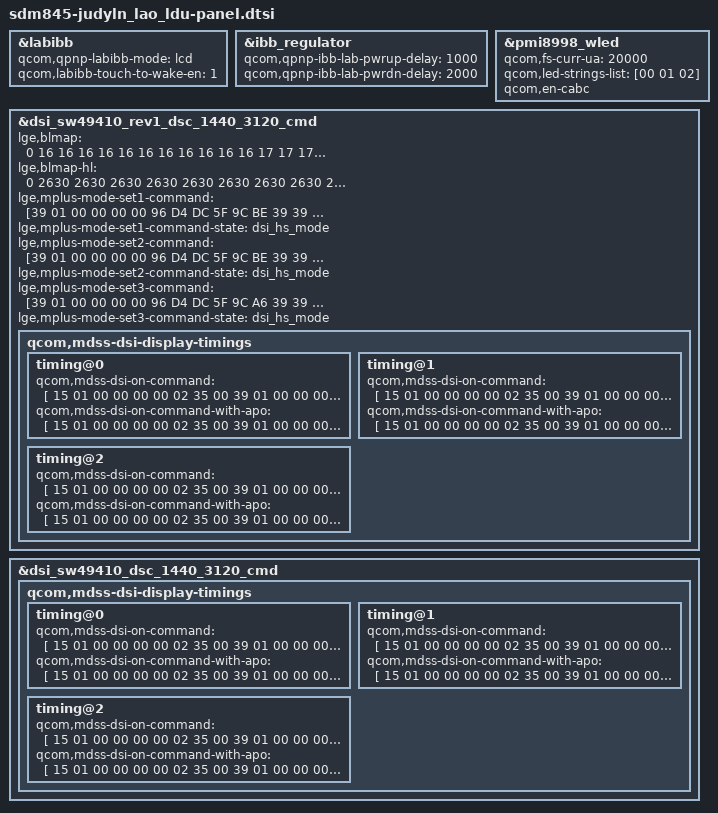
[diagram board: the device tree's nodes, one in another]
/* Copyright (c) 2017, The Linux Foundation. All rights reserved.
 *
 * This program is free software; you can redistribute it and/or modify
 * it under the terms of the GNU General Public License version 2 and
 * only version 2 as published by the Free Software Foundation.
 *
 * This program is distributed in the hope that it will be useful,
 * but WITHOUT ANY WARRANTY; without even the implied warranty of
 * MERCHANTABILITY or FITNESS FOR A PARTICULAR PURPOSE.  See the
 * GNU General Public License for more details.
 */

#include "../sdm845-judy_common/sdm845-judy_common-panel.dtsi"

&labibb {
	status = "ok";
	qcom,qpnp-labibb-mode = "lcd";
	qcom,labibb-touch-to-wake-en = <1>;
};

&ibb_regulator {
	qcom,qpnp-ibb-lab-pwrup-delay = <1000>;
	qcom,qpnp-ibb-lab-pwrdn-delay = <2000>;
};

&pmi8998_wled {
	status = "okay";
	qcom,fs-curr-ua = <20000>;
	qcom,led-strings-list = [00 01 02];
	qcom,en-cabc;
	/delete-property/ qcom,auto-calibration-enable;
};

&dsi_sw49410_rev1_dsc_1440_3120_cmd {
	lge,blmap = <
		0
		16 16 16 16 16 16 16 16 16 16 16 17 17 17 18 18 18 18 19 19
		19 20 20 21 22 23 24 25 26 27 28 29 30 31 32 34 36 38 40 42
		44 45 47 49 51 53 55 57 60 63 66 69 72 75 78 81 84 87 90 93
		97 101 105 109 113 118 122 126 130 134 138 142 147 152 157 162 167 173 178 183
		188 193 198 203 209 215 221 227 233 239 244 250 256 262 268 274 280 287 295 302
		309 317 324 331 339 346 353 361 368 377 386 394 403 412 421 429 438 447 456 464
		473 482 492 501 511 520 530 539 548 558 567 577 586 596 606 616 626 636 646 655
		665 675 685 695 705 715 727 739 751 763 775 788 800 812 824 836 848 860 873 887
		900 913 926 940 953 966 979 993 1006 1019 1034 1048 1063 1077 1092 1107 1121 1136 1150 1165
		1179 1194 1209 1223 1238 1253 1267 1282 1297 1312 1326 1341 1356 1370 1385 1403 1420 1438 1456 1473
		1491 1509 1526 1544 1562 1579 1597 1616 1635 1654 1673 1692 1711 1730 1749 1768 1787 1806 1825 1846
		1866 1887 1908 1928 1949 1970 1990 2011 2032 2052 2073 2093 2114 2134 2155 2175 2195 2216 2236 2256
		2277 2297 2318 2338 2365 2391 2418 2444 2471 2497 2524 2550 2577 2603 2630
	>;

	lge,blmap-hl = <
		0
		2630 2630 2630 2630 2630 2630 2630 2630 2630 2630
	>;

	lge,mplus-mode-set1-command = [39 01 00 00 00 00 96 D4 DC 5F 9C BE 39 39 39 47 48 48 48 3A 00 03 6D 80 00 00 8C 66 00 00 8C 66 00 00 8C 66 00 0A 48 80 00 0A 48 80 00 0A 48 80 00 0A 48 80 20 0A 14 0A 18 00 23 9E 23 9E 23 9E 01 01 01 01 04 04 04 04 01 00 02 80 00 10 00 10 00 10 13 9E 13 9E 13 9E 13 9E 05 05 05 05 05 05 05 05 23 9E FF FF 16 66 18 00 16 66 10 00 FF 01 00 02 00 03 00 04 00 05 00 06 00 07 00 08 00 09 00 0A 00 0B 00 0C 00 0D 00 0E 00 0F 00 1B 25 DC 18 00 20 00 1C E1 00 FF E0 C8 C8 41 8F];
	lge,mplus-mode-set1-command-state = "dsi_hs_mode";

	lge,mplus-mode-set2-command = [39 01 00 00 00 00 96 D4 DC 5F 9C BE 39 39 39 47 48 48 48 3A 00 03 6D 80 00 00 8C 66 00 00 8C 66 00 00 8C 66 00 0A 48 80 00 0A 48 80 00 0A 48 80 00 0A 48 80 20 0A 14 0A 18 00 23 9E 23 9E 23 9E 01 01 01 01 04 04 04 04 01 00 02 80 00 10 00 10 00 10 13 9E 13 9E 13 9E 13 9E 05 05 05 05 05 05 05 05 23 9E FF FF 16 66 18 00 16 66 10 00 FF 01 00 02 00 03 00 04 00 05 00 06 00 07 00 08 00 09 00 0A 00 0B 00 0C 00 0D 00 0E 00 0F 00 1B 25 DC 18 00 20 00 1C E1 00 FF E0 C8 C8 41 8F];
	lge,mplus-mode-set2-command-state = "dsi_hs_mode";

	lge,mplus-mode-set3-command = [39 01 00 00 00 00 96 D4 DC 5F 9C A6 39 39 39 47 48 48 48 3A 00 22 47 00 00 2F FD 00 00 22 47 00 00 0D B6 00 00 89 1C 00 00 2F FD 00 00 22 47 00 00 0D B6 00 20 00 00 00 18 00 23 9E 23 9E 23 9E 06 06 06 06 05 05 05 05 01 00 02 80 00 C8 01 80 00 30 13 9E 13 9E 13 9E 13 9E 10 10 10 10 10 10 10 10 23 9E FF FF 18 00 18 00 16 66 10 00 FF 01 00 02 00 03 00 04 00 05 00 06 00 07 00 08 00 09 00 0A 00 0B 00 0C 00 0D 00 0E 00 0F 00 1B 25 DC 18 00 20 00 1C E1 00 FF E0 C8 C8 41 8F];
	lge,mplus-mode-set3-command-state = "dsi_hs_mode";
	qcom,mdss-dsi-display-timings {
		timing@0{
			qcom,mdss-dsi-on-command = [
				/* TE On */
				15 01 00 00 00 00 02 35 00
				/* Page Address Set */
				39 01 00 00 00 00 05 2B 00 00 0C 2F
				/* BLU Control */
				15 01 00 00 00 00 02 51 FF
				15 01 00 00 00 00 02 53 2C
				15 01 00 00 00 00 02 5E 00
				15 01 00 00 00 00 02 55 81
				/*Manufacturer protection*/
				15 01 00 00 00 00 02 B0 AC
				/*Source Control*/
				39 01 00 00 00 00 09 B3 04 04 28 08 5A 12 23 02
				/*Gate & Mux Control*/
				39 01 00 00 00 00 20 B4 11 04 02 02 02 02 02 01 01 01 01 01 01 D0 E4 E4 E4 93 4E 39 0A 10 18 25 24 00 00 00 00 00 00
				/*Sync Setup*/
				39 01 00 00 00 00 09 B5 2E 0F 10 C0 00 10 C0 00
				/*Panel Setting*/
				39 01 00 00 00 00 06 B6 03 05 0B B3 30
				/*Touch Timing Control*/
				39 01 00 00 00 00 20 B8 57 02 90 40 5D D0 05 00 00 18 22 04 01 02 90 40 4C C0 04 00 00 18 22 04 01 08 00 3A 86 83 00
				/*Touch Source Setting*/
				39 01 00 00 00 00 06 B9 64 64 2A 3F EE
				/*DSC Configuration*/
				39 01 00 00 00 00 0C BA 3D 1F 01 FF 01 3C 1F 01 FF 01 00
				/*Low Rate Refresh Setting*/
				39 01 00 00 00 00 05 BC 00 00 00 10
				/*Black Frame Setting*/
				39 01 00 00 00 00 03 BD 00 00
				/* U2 Corner Down */
				39 01 00 00 00 00 03 BF 4F 02
				/*Internal Oscillator Setting*/
				39 01 00 00 00 00 0B C0 00 04 18 07 11 11 3C 00 0A 0A
				/*Power Control1*/
				39 01 00 00 00 00 07 C1 01 00 F0 C2 CF 0C
				/*Power Control2*/
				39 01 00 00 00 00 09 C2 CC 44 44 20 22 26 21 00
				/*Power Control3*/
				39 01 00 00 00 00 13 C3 92 11 09 09 11 CC 02 02 A4 A4 02 A2 38 28 14 40 38 C0
				/*Vcom Setting*/
				39 01 00 00 00 00 03 C4 26 00
				/*Power Sequence Option Configuration*/
				39 01 00 00 00 00 06 C9 05 5D 03 04 00
				/*Abrupt Power Off Control*/
				39 01 00 00 00 00 03 CA 9B 10
				/*LFD Control*/
				39 01 00 00 00 00 06 CB F3 90 3D 30 CC
				/*Tail TFT Setting*/
				39 01 00 00 00 00 06 CC 00 40 50 90 41
				/*U2 Option*/
				39 01 00 00 00 00 03 CE 00 00
				/*Gamma*/
				39 01 00 00 00 00 A9 D0 12 05 20 1B 2C 28 3F 3D 4F 4F 66 66 6E 6E 76 76 80 80 88 88 95 95 3F 3F A2 A2 94 94 8B 8B 81 81 75 75 66 66 47 47 2D 2D 00 01 12 05 20 1B 2C 28 3F 3D 4f 4f 66 66 6e 6e 76 76 80 80 88 88 95 95 3F 3F A2 A2 94 94 8b 8b 81 81 75 75 66 66 47 47 2d 2d 00 01 12 05 20 1B 2C 28 3F 3D 4f 4f 66 66 6e 6e 76 76 80 80 88 88 95 95 3F 3F A2 A2 94 94 8b 8b 81 81 75 75 66 66 47 47 2d 2d 00 01 12 05 20 1B 2C 28 3F 3D 4f 4f 66 66 6e 6e 76 76 80 80 88 88 94 94 3F 3F A4 A4 95 95 8b 8b 81 81 75 75 66 66 47 47 2d 2d 00 01
				39 01 00 00 00 00 A9 D1 12 05 20 1B 2C 28 3F 3D 4F 4F 66 66 6E 6E 76 76 80 80 88 88 95 95 3F 3F A2 A2 94 94 8B 8B 81 81 75 75 66 66 47 47 2D 2D 00 01 12 05 20 1B 2C 28 3F 3D 4f 4f 66 66 6e 6e 76 76 80 80 88 88 95 95 3F 3F A2 A2 94 94 8b 8b 81 81 75 75 66 66 47 47 2d 2d 00 01 12 05 20 1B 2C 28 3F 3D 4f 4f 66 66 6e 6e 76 76 80 80 88 88 95 95 3F 3F A2 A2 94 94 8b 8b 81 81 75 75 66 66 47 47 2d 2d 00 01 12 05 20 1B 2C 28 3F 3D 4f 4f 66 66 6e 6e 76 76 80 80 88 88 94 94 3F 3F A4 A4 95 95 8b 8b 81 81 75 75 66 66 47 47 2d 2d 00 01
				39 01 00 00 00 00 A9 D2 12 05 20 1B 2C 28 3F 3D 4F 4F 66 66 6E 6E 76 76 80 80 88 88 95 95 3F 3F A2 A2 94 94 8B 8B 81 81 75 75 66 66 47 47 2D 2D 00 01 12 05 20 1B 2C 28 3F 3D 4f 4f 66 66 6e 6e 76 76 80 80 88 88 95 95 3F 3F A2 A2 94 94 8b 8b 81 81 75 75 66 66 47 47 2d 2d 00 01 12 05 20 1B 2C 28 3F 3D 4f 4f 66 66 6e 6e 76 76 80 80 88 88 95 95 3F 3F A2 A2 94 94 8b 8b 81 81 75 75 66 66 47 47 2d 2d 00 01 12 05 20 1B 2C 28 3F 3D 4f 4f 66 66 6e 6e 76 76 80 80 88 88 94 94 3F 3F A4 A4 95 95 8b 8b 81 81 75 75 66 66 47 47 2d 2d 00 01
				/* MPLUS Control */
				39 01 00 00 00 00 05 D3 12 01 00 00
				/*Mplus Setting*/
				39 01 00 00 00 00 96 D4 DC 5F 9C BE 39 39 39 47 48 48 48 3A 00 03 6D 80 00 00 8C 66 00 00 8C 66 00 00 8C 66 00 0A 48 80 00 0A 48 80 00 0A 48 80 00 0A 48 80 20 0A 14 0A 18 00 23 9E 23 9E 23 9E 01 01 01 01 04 04 04 04 01 00 02 80 00 10 00 10 00 10 13 9E 13 9E 13 9E 13 9E 05 05 05 05 05 05 05 05 23 9E FF FF 16 66 18 00 16 66 10 00 FF 01 00 02 00 03 00 04 00 05 00 06 00 07 00 08 00 09 00 0A 00 0B 00 0C 00 0D 00 0E 00 0F 00 1B 25 DC 18 00 20 00 1C E1 00 FF E0 C8 C8 41 8F
				/*Notch Up Gradation*/
				39 01 00 00 00 00 21 AD 01 02 03 04 05 06 06 06 06 06 06 06 06 06 06 06 20 40 60 90 C0 F0 FF FF FF FF FF FF FF FF FF FF
				/*Notch Down Gradation*/
				39 01 00 00 00 00 21 AE 01 02 03 04 05 06 06 06 06 06 06 06 06 06 06 06 20 40 60 90 C0 F0 FF FF FF FF FF FF FF FF FF FF
				/*GIP Setting*/
				39 01 00 00 00 00 1B E5 0B 0A 0C 00 02 04 06 08 0F 1B 02 1A 1A 0B 0A 0C 01 03 05 07 09 10 1B 03 1A 1A
				/*Mux Setting*/
				39 01 00 00 00 00 11 E6 11 12 13 14 15 16 17 18 11 12 13 14 15 16 17 18
				/*Test1*/
				39 01 00 00 00 00 07 ED 21 49 00 00 00 00
				/*BLU Control*/
				15 01 00 00 00 00 02 55 81
				/*Sharpness*/
				39 01 00 00 00 00 06 F3 00 01 00 0D 00
				39 01 00 00 00 00 0E F4 00 00 40 83 C5 00 01 00 00 00 00 00 00
				39 01 00 00 00 00 18 FB 20 40 60 80 a0 c0 e0 13 18 18 18 16 0D 0D 00 C7 CF D8 E1 EA F3 F9 FF
				/*Gamma Correction*/
				39 01 00 00 00 00 02 F5 00
				39 01 00 00 00 00 11 F6 40 40 40 40 40 40 40 40 00 00 00 00 00 00 00 00
				39 01 00 00 00 00 11 F7 40 40 40 40 40 40 40 40 00 00 00 00 00 00 00 00
				39 01 00 00 00 00 11 F8 40 40 40 40 40 40 40 40 00 00 00 00 00 00 00 00
				/*BLU PWM Control*/
				39 01 00 00 00 00 0E FC 13 70 D0 26 30 7C 02 FF 12 22 22 10 00
				/* Normal Display mode on */
				05 01 00 00 00 00 01 13
				/* Sleep Out + min 120ms */
				05 01 00 00 80 00 01 11
				/*Black Frame Setting*/
				39 01 00 00 00 00 03 BD 01 05
				05 01 00 00 05 00 01 29
			];

			qcom,mdss-dsi-on-command-with-apo = [
				/* TE On */
				15 01 00 00 00 00 02 35 00
				/* Page Address Set */
				39 01 00 00 00 00 05 2B 00 00 0C 2F
				/* BLU Control */
				15 01 00 00 00 00 02 51 FF
				15 01 00 00 00 00 02 53 2C
				15 01 00 00 00 00 02 5E 00
				15 01 00 00 00 00 02 55 81
				/*Manufacturer protection*/
				15 01 00 00 00 00 02 B0 AC
				/*Source Control*/
				39 01 00 00 00 00 09 B3 04 04 28 08 5A 12 23 02
				/*Gate & Mux Control*/
				39 01 00 00 00 00 20 B4 11 04 02 02 02 02 02 01 01 01 01 01 01 D0 E4 E4 E4 93 4E 39 0A 10 18 25 24 00 00 00 00 00 00
				/*Sync Setup*/
				39 01 00 00 00 00 09 B5 2E 0F 10 C0 00 10 C0 00
				/*Panel Setting*/
				39 01 00 00 00 00 06 B6 03 05 0B B3 30
				/*Touch Timing Control*/
				39 01 00 00 00 00 20 B8 57 02 90 40 5D D0 05 00 00 18 22 04 01 02 90 40 4C C0 04 00 00 18 22 04 01 08 00 3A 86 83 00
				/*Touch Source Setting*/
				39 01 00 00 00 00 06 B9 64 64 2A 3F EE
				/*DSC Configuration*/
				39 01 00 00 00 00 0C BA 3D 1F 01 FF 01 3C 1F 01 FF 01 00
				/*Low Rate Refresh Setting*/
				39 01 00 00 00 00 05 BC 00 00 00 10
				/*Black Frame Setting*/
				39 01 00 00 00 00 03 BD 00 00
				/* U2 Corner Down */
				39 01 00 00 00 00 03 BF 4F 02
				/*Internal Oscillator Setting*/
				39 01 00 00 00 00 0B C0 00 04 18 07 11 11 3C 00 0A 0A
				/*Power Control1*/
				39 01 00 00 00 00 07 C1 01 00 F0 C2 CF 0C
				/*Power Control2*/
				39 01 00 00 00 00 09 C2 CC 44 44 20 22 26 21 00
				/*Power Control3*/
				39 01 00 00 00 00 13 C3 92 11 09 09 11 CC 02 02 A4 A4 02 A2 38 28 14 40 38 C0
				/*Vcom Setting*/
				39 01 00 00 00 00 03 C4 26 00
				/*Power Sequence Option Configuration - source & vcom GND*/
				39 01 00 00 00 00 06 C9 01 54 03 04 00
				/*Abrupt Power Off Control*/
				39 01 00 00 00 00 03 CA 9B 10
				/*LFD Control*/
				39 01 00 00 00 00 06 CB F3 90 3D 30 CC
				/*Tail TFT Setting*/
				39 01 00 00 00 00 06 CC 00 40 50 90 41
				/*U2 Option*/
				39 01 00 00 00 00 03 CE 00 00
				/*Gamma*/
				39 01 00 00 00 00 A9 D0 12 05 20 1B 2C 28 3F 3D 4F 4F 66 66 6E 6E 76 76 80 80 88 88 95 95 3F 3F A2 A2 94 94 8B 8B 81 81 75 75 66 66 47 47 2D 2D 00 01 12 05 20 1B 2C 28 3F 3D 4f 4f 66 66 6e 6e 76 76 80 80 88 88 95 95 3F 3F A2 A2 94 94 8b 8b 81 81 75 75 66 66 47 47 2d 2d 00 01 12 05 20 1B 2C 28 3F 3D 4f 4f 66 66 6e 6e 76 76 80 80 88 88 95 95 3F 3F A2 A2 94 94 8b 8b 81 81 75 75 66 66 47 47 2d 2d 00 01 12 05 20 1B 2C 28 3F 3D 4f 4f 66 66 6e 6e 76 76 80 80 88 88 94 94 3F 3F A4 A4 95 95 8b 8b 81 81 75 75 66 66 47 47 2d 2d 00 01
				39 01 00 00 00 00 A9 D1 12 05 20 1B 2C 28 3F 3D 4F 4F 66 66 6E 6E 76 76 80 80 88 88 95 95 3F 3F A2 A2 94 94 8B 8B 81 81 75 75 66 66 47 47 2D 2D 00 01 12 05 20 1B 2C 28 3F 3D 4f 4f 66 66 6e 6e 76 76 80 80 88 88 95 95 3F 3F A2 A2 94 94 8b 8b 81 81 75 75 66 66 47 47 2d 2d 00 01 12 05 20 1B 2C 28 3F 3D 4f 4f 66 66 6e 6e 76 76 80 80 88 88 95 95 3F 3F A2 A2 94 94 8b 8b 81 81 75 75 66 66 47 47 2d 2d 00 01 12 05 20 1B 2C 28 3F 3D 4f 4f 66 66 6e 6e 76 76 80 80 88 88 94 94 3F 3F A4 A4 95 95 8b 8b 81 81 75 75 66 66 47 47 2d 2d 00 01
				39 01 00 00 00 00 A9 D2 12 05 20 1B 2C 28 3F 3D 4F 4F 66 66 6E 6E 76 76 80 80 88 88 95 95 3F 3F A2 A2 94 94 8B 8B 81 81 75 75 66 66 47 47 2D 2D 00 01 12 05 20 1B 2C 28 3F 3D 4f 4f 66 66 6e 6e 76 76 80 80 88 88 95 95 3F 3F A2 A2 94 94 8b 8b 81 81 75 75 66 66 47 47 2d 2d 00 01 12 05 20 1B 2C 28 3F 3D 4f 4f 66 66 6e 6e 76 76 80 80 88 88 95 95 3F 3F A2 A2 94 94 8b 8b 81 81 75 75 66 66 47 47 2d 2d 00 01 12 05 20 1B 2C 28 3F 3D 4f 4f 66 66 6e 6e 76 76 80 80 88 88 94 94 3F 3F A4 A4 95 95 8b 8b 81 81 75 75 66 66 47 47 2d 2d 00 01
				/* MPLUS Control */
				39 01 00 00 00 00 05 D3 12 01 00 00
				/*Mplus Setting*/
				39 01 00 00 00 00 96 D4 DC 5F 9C BE 39 39 39 47 48 48 48 3A 00 03 6D 80 00 00 8C 66 00 00 8C 66 00 00 8C 66 00 0A 48 80 00 0A 48 80 00 0A 48 80 00 0A 48 80 20 0A 14 0A 18 00 23 9E 23 9E 23 9E 01 01 01 01 04 04 04 04 01 00 02 80 00 10 00 10 00 10 13 9E 13 9E 13 9E 13 9E 05 05 05 05 05 05 05 05 23 9E FF FF 16 66 18 00 16 66 10 00 FF 01 00 02 00 03 00 04 00 05 00 06 00 07 00 08 00 09 00 0A 00 0B 00 0C 00 0D 00 0E 00 0F 00 1B 25 DC 18 00 20 00 1C E1 00 FF E0 C8 C8 41 8F
				/*Notch Up Gradation*/
				39 01 00 00 00 00 21 AD 01 02 03 04 05 06 06 06 06 06 06 06 06 06 06 06 20 40 60 90 C0 F0 FF FF FF FF FF FF FF FF FF FF
				/*Notch Down Gradation*/
				39 01 00 00 00 00 21 AE 01 02 03 04 05 06 06 06 06 06 06 06 06 06 06 06 20 40 60 90 C0 F0 FF FF FF FF FF FF FF FF FF FF
				/*GIP Setting*/
				39 01 00 00 00 00 1B E5 0B 0A 0C 00 02 04 06 08 0F 1B 02 1A 1A 0B 0A 0C 01 03 05 07 09 10 1B 03 1A 1A
				/*Mux Setting*/
				39 01 00 00 00 00 11 E6 11 12 13 14 15 16 17 18 11 12 13 14 15 16 17 18
				/*Test1*/
				39 01 00 00 00 00 07 ED 21 49 00 00 00 00
				/*BLU Control*/
				15 01 00 00 00 00 02 55 81
				/*Sharpness*/
				39 01 00 00 00 00 06 F3 00 01 00 0D 00
				39 01 00 00 00 00 0E F4 00 00 40 83 C5 00 01 00 00 00 00 00 00
				39 01 00 00 00 00 18 FB 20 40 60 80 a0 c0 e0 13 18 18 18 16 0D 0D 00 C7 CF D8 E1 EA F3 F9 FF
				/*Gamma Correction*/
				39 01 00 00 00 00 02 F5 00
				39 01 00 00 00 00 11 F6 40 40 40 40 40 40 40 40 00 00 00 00 00 00 00 00
				39 01 00 00 00 00 11 F7 40 40 40 40 40 40 40 40 00 00 00 00 00 00 00 00
				39 01 00 00 00 00 11 F8 40 40 40 40 40 40 40 40 00 00 00 00 00 00 00 00
				/*BLU PWM Control*/
				39 01 00 00 00 00 0E FC 13 70 D0 26 30 7C 02 FF 12 22 22 10 00
				/* Normal Display mode on */
				05 01 00 00 00 00 01 13
				/* Sleep Out + min 120ms */
				05 01 00 00 80 00 01 11
				/*GIP Setting - APO high*/
				39 01 00 00 64 00 1B E5 0B 0A 1C 00 02 04 06 08 0F 1B 02 1A 1A 0B 0A 1C 01 03 05 07 09 10 1B 03 1A 1A
				/*Power Sequence Option Configuration*/
				39 01 00 00 00 00 06 C9 05 5D 03 04 00
				/*GIP Setting*/
				39 01 00 00 00 00 1B E5 0B 0A 0C 00 02 04 06 08 0F 1B 02 1A 1A 0B 0A 0C 01 03 05 07 09 10 1B 03 1A 1A
				/*Black Frame Setting*/
				39 01 00 00 00 00 03 BD 01 05
				05 01 00 00 05 00 01 29
			];
		};
		timing@1{
			qcom,mdss-dsi-on-command = [
				/* TE On */
				15 01 00 00 00 00 02 35 00
				/* Page Address Set */
				39 01 00 00 00 00 05 2B 00 00 0C 2F
				/* BLU Control */
				15 01 00 00 00 00 02 51 FF
				15 01 00 00 00 00 02 53 2C
				15 01 00 00 00 00 02 5E 00
				15 01 00 00 00 00 02 55 81
				/*Manufacturer protection*/
				15 01 00 00 00 00 02 B0 AC
				/*Source Control*/
				39 01 00 00 00 00 09 B3 04 04 28 08 5A 12 23 02
				/*Gate & Mux Control*/
				39 01 00 00 00 00 20 B4 11 04 02 02 02 02 02 01 01 01 01 01 01 D0 E4 E4 E4 93 4E 39 0A 10 18 25 24 00 00 00 00 00 00
				/*Sync Setup*/
				39 01 00 00 00 00 09 B5 2E 0F 10 C0 00 10 C0 00
				/*Panel Setting*/
				39 01 00 00 00 00 06 B6 03 05 0B B3 30
				/*Touch Timing Control*/
				39 01 00 00 00 00 20 B8 57 02 90 40 5D D0 05 00 00 18 22 04 01 02 90 40 4C C0 04 00 00 18 22 04 01 08 00 3A 86 83 00
				/*Touch Source Setting*/
				39 01 00 00 00 00 06 B9 64 64 2A 3F EE
				/*DSC Configuration*/
				39 01 00 00 00 00 0C BA 3D 1F 01 FF 01 3C 1F 01 FF 01 00
				/*Low Rate Refresh Setting*/
				39 01 00 00 00 00 05 BC 00 00 00 10
				/*Black Frame Setting*/
				39 01 00 00 00 00 03 BD 00 00
				/* U2 Corner Down */
				39 01 00 00 00 00 03 BF 4F 02
				/*Internal Oscillator Setting*/
				39 01 00 00 00 00 0B C0 00 04 18 07 11 11 3C 00 0A 0A
				/*Power Control1*/
				39 01 00 00 00 00 07 C1 01 00 F0 C2 CF 0C
				/*Power Control2*/
				39 01 00 00 00 00 09 C2 CC 44 44 20 22 26 21 00
				/*Power Control3*/
				39 01 00 00 00 00 13 C3 92 11 09 09 11 CC 02 02 A4 A4 02 A2 38 28 14 40 38 C0
				/*Vcom Setting*/
				39 01 00 00 00 00 03 C4 26 00
				/*Power Sequence Option Configuration*/
				39 01 00 00 00 00 06 C9 05 5D 03 04 00
				/*Abrupt Power Off Control*/
				39 01 00 00 00 00 03 CA 9B 10
				/*LFD Control*/
				39 01 00 00 00 00 06 CB F3 90 3D 30 CC
				/*Tail TFT Setting*/
				39 01 00 00 00 00 06 CC 00 40 50 90 41
				/*U2 Option*/
				39 01 00 00 00 00 03 CE 00 00
				/*Gamma*/
				39 01 00 00 00 00 A9 D0 12 05 20 1B 2C 28 3F 3D 4F 4F 66 66 6E 6E 76 76 80 80 88 88 95 95 3F 3F A2 A2 94 94 8B 8B 81 81 75 75 66 66 47 47 2D 2D 00 01 12 05 20 1B 2C 28 3F 3D 4f 4f 66 66 6e 6e 76 76 80 80 88 88 95 95 3F 3F A2 A2 94 94 8b 8b 81 81 75 75 66 66 47 47 2d 2d 00 01 12 05 20 1B 2C 28 3F 3D 4f 4f 66 66 6e 6e 76 76 80 80 88 88 95 95 3F 3F A2 A2 94 94 8b 8b 81 81 75 75 66 66 47 47 2d 2d 00 01 12 05 20 1B 2C 28 3F 3D 4f 4f 66 66 6e 6e 76 76 80 80 88 88 94 94 3F 3F A4 A4 95 95 8b 8b 81 81 75 75 66 66 47 47 2d 2d 00 01
				39 01 00 00 00 00 A9 D1 12 05 20 1B 2C 28 3F 3D 4F 4F 66 66 6E 6E 76 76 80 80 88 88 95 95 3F 3F A2 A2 94 94 8B 8B 81 81 75 75 66 66 47 47 2D 2D 00 01 12 05 20 1B 2C 28 3F 3D 4f 4f 66 66 6e 6e 76 76 80 80 88 88 95 95 3F 3F A2 A2 94 94 8b 8b 81 81 75 75 66 66 47 47 2d 2d 00 01 12 05 20 1B 2C 28 3F 3D 4f 4f 66 66 6e 6e 76 76 80 80 88 88 95 95 3F 3F A2 A2 94 94 8b 8b 81 81 75 75 66 66 47 47 2d 2d 00 01 12 05 20 1B 2C 28 3F 3D 4f 4f 66 66 6e 6e 76 76 80 80 88 88 94 94 3F 3F A4 A4 95 95 8b 8b 81 81 75 75 66 66 47 47 2d 2d 00 01
				39 01 00 00 00 00 A9 D2 12 05 20 1B 2C 28 3F 3D 4F 4F 66 66 6E 6E 76 76 80 80 88 88 95 95 3F 3F A2 A2 94 94 8B 8B 81 81 75 75 66 66 47 47 2D 2D 00 01 12 05 20 1B 2C 28 3F 3D 4f 4f 66 66 6e 6e 76 76 80 80 88 88 95 95 3F 3F A2 A2 94 94 8b 8b 81 81 75 75 66 66 47 47 2d 2d 00 01 12 05 20 1B 2C 28 3F 3D 4f 4f 66 66 6e 6e 76 76 80 80 88 88 95 95 3F 3F A2 A2 94 94 8b 8b 81 81 75 75 66 66 47 47 2d 2d 00 01 12 05 20 1B 2C 28 3F 3D 4f 4f 66 66 6e 6e 76 76 80 80 88 88 94 94 3F 3F A4 A4 95 95 8b 8b 81 81 75 75 66 66 47 47 2d 2d 00 01
				/* MPLUS Control */
				39 01 00 00 00 00 05 D3 12 01 00 00
				/*Mplus Setting*/
				39 01 00 00 00 00 96 D4 DC 5F 9C BE 39 39 39 47 48 48 48 3A 00 03 6D 80 00 00 8C 66 00 00 8C 66 00 00 8C 66 00 0A 48 80 00 0A 48 80 00 0A 48 80 00 0A 48 80 20 0A 14 0A 18 00 23 9E 23 9E 23 9E 01 01 01 01 04 04 04 04 01 00 02 80 00 10 00 10 00 10 13 9E 13 9E 13 9E 13 9E 05 05 05 05 05 05 05 05 23 9E FF FF 16 66 18 00 16 66 10 00 FF 01 00 02 00 03 00 04 00 05 00 06 00 07 00 08 00 09 00 0A 00 0B 00 0C 00 0D 00 0E 00 0F 00 1B 25 DC 18 00 20 00 1C E1 00 FF E0 C8 C8 41 8F
				/*Notch Up Gradation*/
				39 01 00 00 00 00 21 AD 01 02 03 04 05 06 06 06 06 06 06 06 06 06 06 06 20 40 60 90 C0 F0 FF FF FF FF FF FF FF FF FF FF
				/*Notch Down Gradation*/
				39 01 00 00 00 00 21 AE 01 02 03 04 05 06 06 06 06 06 06 06 06 06 06 06 20 40 60 90 C0 F0 FF FF FF FF FF FF FF FF FF FF
				/*GIP Setting*/
				39 01 00 00 00 00 1B E5 0B 0A 0C 00 02 04 06 08 0F 1B 02 1A 1A 0B 0A 0C 01 03 05 07 09 10 1B 03 1A 1A
				/*Mux Setting*/
				39 01 00 00 00 00 11 E6 11 12 13 14 15 16 17 18 11 12 13 14 15 16 17 18
				/*Test1*/
				39 01 00 00 00 00 07 ED 21 49 00 00 00 00
				/*BLU Control*/
				15 01 00 00 00 00 02 55 81
				/*Sharpness*/
				39 01 00 00 00 00 06 F3 00 01 00 0D 00
				39 01 00 00 00 00 0E F4 00 00 40 83 C5 00 01 00 00 00 00 00 00
				39 01 00 00 00 00 18 FB 20 40 60 80 a0 c0 e0 13 18 18 18 16 0D 0D 00 C7 CF D8 E1 EA F3 F9 FF
				/*Gamma Correction*/
				39 01 00 00 00 00 02 F5 00
				39 01 00 00 00 00 11 F6 40 40 40 40 40 40 40 40 00 00 00 00 00 00 00 00
				39 01 00 00 00 00 11 F7 40 40 40 40 40 40 40 40 00 00 00 00 00 00 00 00
				39 01 00 00 00 00 11 F8 40 40 40 40 40 40 40 40 00 00 00 00 00 00 00 00
				/*BLU PWM Control*/
				39 01 00 00 00 00 0E FC 13 70 D0 26 30 7C 02 FF 12 22 22 10 00
				/* Normal Display mode on */
				05 01 00 00 00 00 01 13
				/* Sleep Out + min 120ms */
				05 01 00 00 80 00 01 11
				/*Black Frame Setting*/
				39 01 00 00 00 00 03 BD 01 05
				05 01 00 00 05 00 01 29
			];

			qcom,mdss-dsi-on-command-with-apo = [
				/* TE On */
				15 01 00 00 00 00 02 35 00
				/* Page Address Set */
				39 01 00 00 00 00 05 2B 00 00 0C 2F
				/* BLU Control */
				15 01 00 00 00 00 02 51 FF
				15 01 00 00 00 00 02 53 2C
				15 01 00 00 00 00 02 5E 00
				15 01 00 00 00 00 02 55 81
				/*Manufacturer protection*/
				15 01 00 00 00 00 02 B0 AC
				/*Source Control*/
				39 01 00 00 00 00 09 B3 04 04 28 08 5A 12 23 02
				/*Gate & Mux Control*/
				39 01 00 00 00 00 20 B4 11 04 02 02 02 02 02 01 01 01 01 01 01 D0 E4 E4 E4 93 4E 39 0A 10 18 25 24 00 00 00 00 00 00
				/*Sync Setup*/
				39 01 00 00 00 00 09 B5 2E 0F 10 C0 00 10 C0 00
				/*Panel Setting*/
				39 01 00 00 00 00 06 B6 03 05 0B B3 30
				/*Touch Timing Control*/
				39 01 00 00 00 00 20 B8 57 02 90 40 5D D0 05 00 00 18 22 04 01 02 90 40 4C C0 04 00 00 18 22 04 01 08 00 3A 86 83 00
				/*Touch Source Setting*/
				39 01 00 00 00 00 06 B9 64 64 2A 3F EE
				/*DSC Configuration*/
				39 01 00 00 00 00 0C BA 3D 1F 01 FF 01 3C 1F 01 FF 01 00
				/*Low Rate Refresh Setting*/
				39 01 00 00 00 00 05 BC 00 00 00 10
				/*Black Frame Setting*/
				39 01 00 00 00 00 03 BD 00 00
				/* U2 Corner Down */
				39 01 00 00 00 00 03 BF 4F 02
				/*Internal Oscillator Setting*/
				39 01 00 00 00 00 0B C0 00 04 18 07 11 11 3C 00 0A 0A
				/*Power Control1*/
				39 01 00 00 00 00 07 C1 01 00 F0 C2 CF 0C
				/*Power Control2*/
				39 01 00 00 00 00 09 C2 CC 44 44 20 22 26 21 00
				/*Power Control3*/
				39 01 00 00 00 00 13 C3 92 11 09 09 11 CC 02 02 A4 A4 02 A2 38 28 14 40 38 C0
				/*Vcom Setting*/
				39 01 00 00 00 00 03 C4 26 00
				/*Power Sequence Option Configuration - source & vcom GND*/
				39 01 00 00 00 00 06 C9 01 54 03 04 00
				/*Abrupt Power Off Control*/
				39 01 00 00 00 00 03 CA 9B 10
				/*LFD Control*/
				39 01 00 00 00 00 06 CB F3 90 3D 30 CC
				/*Tail TFT Setting*/
				39 01 00 00 00 00 06 CC 00 40 50 90 41
				/*U2 Option*/
				39 01 00 00 00 00 03 CE 00 00
				/*Gamma*/
				39 01 00 00 00 00 A9 D0 12 05 20 1B 2C 28 3F 3D 4F 4F 66 66 6E 6E 76 76 80 80 88 88 95 95 3F 3F A2 A2 94 94 8B 8B 81 81 75 75 66 66 47 47 2D 2D 00 01 12 05 20 1B 2C 28 3F 3D 4f 4f 66 66 6e 6e 76 76 80 80 88 88 95 95 3F 3F A2 A2 94 94 8b 8b 81 81 75 75 66 66 47 47 2d 2d 00 01 12 05 20 1B 2C 28 3F 3D 4f 4f 66 66 6e 6e 76 76 80 80 88 88 95 95 3F 3F A2 A2 94 94 8b 8b 81 81 75 75 66 66 47 47 2d 2d 00 01 12 05 20 1B 2C 28 3F 3D 4f 4f 66 66 6e 6e 76 76 80 80 88 88 94 94 3F 3F A4 A4 95 95 8b 8b 81 81 75 75 66 66 47 47 2d 2d 00 01
				39 01 00 00 00 00 A9 D1 12 05 20 1B 2C 28 3F 3D 4F 4F 66 66 6E 6E 76 76 80 80 88 88 95 95 3F 3F A2 A2 94 94 8B 8B 81 81 75 75 66 66 47 47 2D 2D 00 01 12 05 20 1B 2C 28 3F 3D 4f 4f 66 66 6e 6e 76 76 80 80 88 88 95 95 3F 3F A2 A2 94 94 8b 8b 81 81 75 75 66 66 47 47 2d 2d 00 01 12 05 20 1B 2C 28 3F 3D 4f 4f 66 66 6e 6e 76 76 80 80 88 88 95 95 3F 3F A2 A2 94 94 8b 8b 81 81 75 75 66 66 47 47 2d 2d 00 01 12 05 20 1B 2C 28 3F 3D 4f 4f 66 66 6e 6e 76 76 80 80 88 88 94 94 3F 3F A4 A4 95 95 8b 8b 81 81 75 75 66 66 47 47 2d 2d 00 01
				39 01 00 00 00 00 A9 D2 12 05 20 1B 2C 28 3F 3D 4F 4F 66 66 6E 6E 76 76 80 80 88 88 95 95 3F 3F A2 A2 94 94 8B 8B 81 81 75 75 66 66 47 47 2D 2D 00 01 12 05 20 1B 2C 28 3F 3D 4f 4f 66 66 6e 6e 76 76 80 80 88 88 95 95 3F 3F A2 A2 94 94 8b 8b 81 81 75 75 66 66 47 47 2d 2d 00 01 12 05 20 1B 2C 28 3F 3D 4f 4f 66 66 6e 6e 76 76 80 80 88 88 95 95 3F 3F A2 A2 94 94 8b 8b 81 81 75 75 66 66 47 47 2d 2d 00 01 12 05 20 1B 2C 28 3F 3D 4f 4f 66 66 6e 6e 76 76 80 80 88 88 94 94 3F 3F A4 A4 95 95 8b 8b 81 81 75 75 66 66 47 47 2d 2d 00 01
				/* MPLUS Control */
				39 01 00 00 00 00 05 D3 12 01 00 00
				/*Mplus Setting*/
				39 01 00 00 00 00 96 D4 DC 5F 9C BE 39 39 39 47 48 48 48 3A 00 03 6D 80 00 00 8C 66 00 00 8C 66 00 00 8C 66 00 0A 48 80 00 0A 48 80 00 0A 48 80 00 0A 48 80 20 0A 14 0A 18 00 23 9E 23 9E 23 9E 01 01 01 01 04 04 04 04 01 00 02 80 00 10 00 10 00 10 13 9E 13 9E 13 9E 13 9E 05 05 05 05 05 05 05 05 23 9E FF FF 16 66 18 00 16 66 10 00 FF 01 00 02 00 03 00 04 00 05 00 06 00 07 00 08 00 09 00 0A 00 0B 00 0C 00 0D 00 0E 00 0F 00 1B 25 DC 18 00 20 00 1C E1 00 FF E0 C8 C8 41 8F
				/*Notch Up Gradation*/
				39 01 00 00 00 00 21 AD 01 02 03 04 05 06 06 06 06 06 06 06 06 06 06 06 20 40 60 90 C0 F0 FF FF FF FF FF FF FF FF FF FF
				/*Notch Down Gradation*/
				39 01 00 00 00 00 21 AE 01 02 03 04 05 06 06 06 06 06 06 06 06 06 06 06 20 40 60 90 C0 F0 FF FF FF FF FF FF FF FF FF FF
				/*GIP Setting*/
				39 01 00 00 00 00 1B E5 0B 0A 0C 00 02 04 06 08 0F 1B 02 1A 1A 0B 0A 0C 01 03 05 07 09 10 1B 03 1A 1A
				/*Mux Setting*/
				39 01 00 00 00 00 11 E6 11 12 13 14 15 16 17 18 11 12 13 14 15 16 17 18
				/*Test1*/
				39 01 00 00 00 00 07 ED 21 49 00 00 00 00
				/*BLU Control*/
				15 01 00 00 00 00 02 55 81
				/*Sharpness*/
				39 01 00 00 00 00 06 F3 00 01 00 0D 00
				39 01 00 00 00 00 0E F4 00 00 40 83 C5 00 01 00 00 00 00 00 00
				39 01 00 00 00 00 18 FB 20 40 60 80 a0 c0 e0 13 18 18 18 16 0D 0D 00 C7 CF D8 E1 EA F3 F9 FF
				/*Gamma Correction*/
				39 01 00 00 00 00 02 F5 00
				39 01 00 00 00 00 11 F6 40 40 40 40 40 40 40 40 00 00 00 00 00 00 00 00
				39 01 00 00 00 00 11 F7 40 40 40 40 40 40 40 40 00 00 00 00 00 00 00 00
				39 01 00 00 00 00 11 F8 40 40 40 40 40 40 40 40 00 00 00 00 00 00 00 00
				/*BLU PWM Control*/
				39 01 00 00 00 00 0E FC 13 70 D0 26 30 7C 02 FF 12 22 22 10 00
				/* Normal Display mode on */
				05 01 00 00 00 00 01 13
				/* Sleep Out + min 120ms */
				05 01 00 00 80 00 01 11
				/*GIP Setting - APO high*/
				39 01 00 00 64 00 1B E5 0B 0A 1C 00 02 04 06 08 0F 1B 02 1A 1A 0B 0A 1C 01 03 05 07 09 10 1B 03 1A 1A
				/*Power Sequence Option Configuration*/
				39 01 00 00 00 00 06 C9 05 5D 03 04 00
				/*GIP Setting*/
				39 01 00 00 00 00 1B E5 0B 0A 0C 00 02 04 06 08 0F 1B 02 1A 1A 0B 0A 0C 01 03 05 07 09 10 1B 03 1A 1A
				/*Black Frame Setting*/
				39 01 00 00 00 00 03 BD 01 05
				05 01 00 00 05 00 01 29
			];
		};
		timing@2{
			qcom,mdss-dsi-on-command = [
				/* TE On */
				15 01 00 00 00 00 02 35 00
				/* Page Address Set */
				39 01 00 00 00 00 05 2B 00 00 0C 2F
				/* BLU Control */
				15 01 00 00 00 00 02 51 FF
				15 01 00 00 00 00 02 53 2C
				15 01 00 00 00 00 02 5E 00
				15 01 00 00 00 00 02 55 81
				/*Manufacturer protection*/
				15 01 00 00 00 00 02 B0 AC
				/*Source Control*/
				39 01 00 00 00 00 09 B3 04 04 28 08 5A 12 23 02
				/*Gate & Mux Control*/
				39 01 00 00 00 00 20 B4 11 04 02 02 02 02 02 01 01 01 01 01 01 D0 E4 E4 E4 93 4E 39 0A 10 18 25 24 00 00 00 00 00 00
				/*Sync Setup*/
				39 01 00 00 00 00 09 B5 2E 0F 10 C0 00 10 C0 00
				/*Panel Setting*/
				39 01 00 00 00 00 06 B6 03 05 0B B3 30
				/*Touch Timing Control*/
				39 01 00 00 00 00 20 B8 57 02 90 40 5D D0 05 00 00 18 22 04 01 02 90 40 4C C0 04 00 00 18 22 04 01 08 00 3A 86 83 00
				/*Touch Source Setting*/
				39 01 00 00 00 00 06 B9 64 64 2A 3F EE
				/*DSC Configuration*/
				39 01 00 00 00 00 0C BA 3D 1F 01 FF 01 3C 1F 01 FF 01 00
				/*Low Rate Refresh Setting*/
				39 01 00 00 00 00 05 BC 00 00 00 10
				/*Black Frame Setting*/
				39 01 00 00 00 00 03 BD 00 00
				/* U2 Corner Down */
				39 01 00 00 00 00 03 BF 4F 02
				/*Internal Oscillator Setting*/
				39 01 00 00 00 00 0B C0 00 04 18 07 11 11 3C 00 0A 0A
				/*Power Control1*/
				39 01 00 00 00 00 07 C1 01 00 F0 C2 CF 0C
				/*Power Control2*/
				39 01 00 00 00 00 09 C2 CC 44 44 20 22 26 21 00
				/*Power Control3*/
				39 01 00 00 00 00 13 C3 92 11 09 09 11 CC 02 02 A4 A4 02 A2 38 28 14 40 38 C0
				/*Vcom Setting*/
				39 01 00 00 00 00 03 C4 26 00
				/*Power Sequence Option Configuration*/
				39 01 00 00 00 00 06 C9 05 5D 03 04 00
				/*Abrupt Power Off Control*/
				39 01 00 00 00 00 03 CA 9B 10
				/*LFD Control*/
				39 01 00 00 00 00 06 CB F3 90 3D 30 CC
				/*Tail TFT Setting*/
				39 01 00 00 00 00 06 CC 00 40 50 90 41
				/*U2 Option*/
				39 01 00 00 00 00 03 CE 00 00
				/*Gamma*/
				39 01 00 00 00 00 A9 D0 12 05 20 1B 2C 28 3F 3D 4F 4F 66 66 6E 6E 76 76 80 80 88 88 95 95 3F 3F A2 A2 94 94 8B 8B 81 81 75 75 66 66 47 47 2D 2D 00 01 12 05 20 1B 2C 28 3F 3D 4f 4f 66 66 6e 6e 76 76 80 80 88 88 95 95 3F 3F A2 A2 94 94 8b 8b 81 81 75 75 66 66 47 47 2d 2d 00 01 12 05 20 1B 2C 28 3F 3D 4f 4f 66 66 6e 6e 76 76 80 80 88 88 95 95 3F 3F A2 A2 94 94 8b 8b 81 81 75 75 66 66 47 47 2d 2d 00 01 12 05 20 1B 2C 28 3F 3D 4f 4f 66 66 6e 6e 76 76 80 80 88 88 94 94 3F 3F A4 A4 95 95 8b 8b 81 81 75 75 66 66 47 47 2d 2d 00 01
				39 01 00 00 00 00 A9 D1 12 05 20 1B 2C 28 3F 3D 4F 4F 66 66 6E 6E 76 76 80 80 88 88 95 95 3F 3F A2 A2 94 94 8B 8B 81 81 75 75 66 66 47 47 2D 2D 00 01 12 05 20 1B 2C 28 3F 3D 4f 4f 66 66 6e 6e 76 76 80 80 88 88 95 95 3F 3F A2 A2 94 94 8b 8b 81 81 75 75 66 66 47 47 2d 2d 00 01 12 05 20 1B 2C 28 3F 3D 4f 4f 66 66 6e 6e 76 76 80 80 88 88 95 95 3F 3F A2 A2 94 94 8b 8b 81 81 75 75 66 66 47 47 2d 2d 00 01 12 05 20 1B 2C 28 3F 3D 4f 4f 66 66 6e 6e 76 76 80 80 88 88 94 94 3F 3F A4 A4 95 95 8b 8b 81 81 75 75 66 66 47 47 2d 2d 00 01
				39 01 00 00 00 00 A9 D2 12 05 20 1B 2C 28 3F 3D 4F 4F 66 66 6E 6E 76 76 80 80 88 88 95 95 3F 3F A2 A2 94 94 8B 8B 81 81 75 75 66 66 47 47 2D 2D 00 01 12 05 20 1B 2C 28 3F 3D 4f 4f 66 66 6e 6e 76 76 80 80 88 88 95 95 3F 3F A2 A2 94 94 8b 8b 81 81 75 75 66 66 47 47 2d 2d 00 01 12 05 20 1B 2C 28 3F 3D 4f 4f 66 66 6e 6e 76 76 80 80 88 88 95 95 3F 3F A2 A2 94 94 8b 8b 81 81 75 75 66 66 47 47 2d 2d 00 01 12 05 20 1B 2C 28 3F 3D 4f 4f 66 66 6e 6e 76 76 80 80 88 88 94 94 3F 3F A4 A4 95 95 8b 8b 81 81 75 75 66 66 47 47 2d 2d 00 01
				/* MPLUS Control */
				39 01 00 00 00 00 05 D3 12 01 00 00
				/*Mplus Setting*/
				39 01 00 00 00 00 96 D4 DC 5F 9C BE 39 39 39 47 48 48 48 3A 00 03 6D 80 00 00 8C 66 00 00 8C 66 00 00 8C 66 00 0A 48 80 00 0A 48 80 00 0A 48 80 00 0A 48 80 20 0A 14 0A 18 00 23 9E 23 9E 23 9E 01 01 01 01 04 04 04 04 01 00 02 80 00 10 00 10 00 10 13 9E 13 9E 13 9E 13 9E 05 05 05 05 05 05 05 05 23 9E FF FF 16 66 18 00 16 66 10 00 FF 01 00 02 00 03 00 04 00 05 00 06 00 07 00 08 00 09 00 0A 00 0B 00 0C 00 0D 00 0E 00 0F 00 1B 25 DC 18 00 20 00 1C E1 00 FF E0 C8 C8 41 8F
				/*Notch Up Gradation*/
				39 01 00 00 00 00 21 AD 01 02 03 04 05 06 06 06 06 06 06 06 06 06 06 06 20 40 60 90 C0 F0 FF FF FF FF FF FF FF FF FF FF
				/*Notch Down Gradation*/
				39 01 00 00 00 00 21 AE 01 02 03 04 05 06 06 06 06 06 06 06 06 06 06 06 20 40 60 90 C0 F0 FF FF FF FF FF FF FF FF FF FF
				/*GIP Setting*/
				39 01 00 00 00 00 1B E5 0B 0A 0C 00 02 04 06 08 0F 1B 02 1A 1A 0B 0A 0C 01 03 05 07 09 10 1B 03 1A 1A
				/*Mux Setting*/
				39 01 00 00 00 00 11 E6 11 12 13 14 15 16 17 18 11 12 13 14 15 16 17 18
				/*Test1*/
				39 01 00 00 00 00 07 ED 21 49 00 00 00 00
				/*BLU Control*/
				15 01 00 00 00 00 02 55 81
				/*Gamma Correction*/
				39 01 00 00 00 00 02 F5 00
				39 01 00 00 00 00 11 F6 40 40 40 40 40 40 40 40 00 00 00 00 00 00 00 00
				39 01 00 00 00 00 11 F7 40 40 40 40 40 40 40 40 00 00 00 00 00 00 00 00
				39 01 00 00 00 00 11 F8 40 40 40 40 40 40 40 40 00 00 00 00 00 00 00 00
				/*Sharpness*/
				39 01 00 00 00 00 06 F3 00 01 00 0D 00
				39 01 00 00 00 00 0E F4 00 00 40 83 C5 00 01 00 00 00 00 00 00
				39 01 00 00 00 00 18 FB 20 40 60 80 a0 c0 e0 13 18 18 18 16 0D 0D 00 C7 CF D8 E1 EA F3 F9 FF
				/*BLU PWM Control*/
				39 01 00 00 00 00 0E FC 13 70 D0 26 30 7C 02 FF 12 22 22 10 00
				/* Normal Display mode on */
				05 01 00 00 00 00 01 13
				/* Sleep Out + min 120ms */
				05 01 00 00 80 00 01 11
				/*Black Frame Setting*/
				39 01 00 00 00 00 03 BD 01 05
				05 01 00 00 05 00 01 29
			];

			qcom,mdss-dsi-on-command-with-apo = [
				/* TE On */
				15 01 00 00 00 00 02 35 00
				/* Page Address Set */
				39 01 00 00 00 00 05 2B 00 00 0C 2F
				/* BLU Control */
				15 01 00 00 00 00 02 51 FF
				15 01 00 00 00 00 02 53 2C
				15 01 00 00 00 00 02 5E 00
				15 01 00 00 00 00 02 55 81
				/*Manufacturer protection*/
				15 01 00 00 00 00 02 B0 AC
				/*Source Control*/
				39 01 00 00 00 00 09 B3 04 04 28 08 5A 12 23 02
				/*Gate & Mux Control*/
				39 01 00 00 00 00 20 B4 11 04 02 02 02 02 02 01 01 01 01 01 01 D0 E4 E4 E4 93 4E 39 0A 10 18 25 24 00 00 00 00 00 00
				/*Sync Setup*/
				39 01 00 00 00 00 09 B5 2E 0F 10 C0 00 10 C0 00
				/*Panel Setting*/
				39 01 00 00 00 00 06 B6 03 05 0B B3 30
				/*Touch Timing Control*/
				39 01 00 00 00 00 20 B8 57 02 90 40 5D D0 05 00 00 18 22 04 01 02 90 40 4C C0 04 00 00 18 22 04 01 08 00 3A 86 83 00
				/*Touch Source Setting*/
				39 01 00 00 00 00 06 B9 64 64 2A 3F EE
				/*DSC Configuration*/
				39 01 00 00 00 00 0C BA 3D 1F 01 FF 01 3C 1F 01 FF 01 00
				/*Low Rate Refresh Setting*/
				39 01 00 00 00 00 05 BC 00 00 00 10
				/*Black Frame Setting*/
				39 01 00 00 00 00 03 BD 00 00
				/* U2 Corner Down */
				39 01 00 00 00 00 03 BF 4F 02
				/*Internal Oscillator Setting*/
				39 01 00 00 00 00 0B C0 00 04 18 07 11 11 3C 00 0A 0A
				/*Power Control1*/
				39 01 00 00 00 00 07 C1 01 00 F0 C2 CF 0C
				/*Power Control2*/
				39 01 00 00 00 00 09 C2 CC 44 44 20 22 26 21 00
				/*Power Control3*/
				39 01 00 00 00 00 13 C3 92 11 09 09 11 CC 02 02 A4 A4 02 A2 38 28 14 40 38 C0
				/*Vcom Setting*/
				39 01 00 00 00 00 03 C4 26 00
				/*Power Sequence Option Configuration - source & vcom GND*/
				39 01 00 00 00 00 06 C9 01 54 03 04 00
				/*Abrupt Power Off Control*/
				39 01 00 00 00 00 03 CA 9B 10
				/*LFD Control*/
				39 01 00 00 00 00 06 CB F3 90 3D 30 CC
				/*Tail TFT Setting*/
				39 01 00 00 00 00 06 CC 00 40 50 90 41
				/*U2 Option*/
				39 01 00 00 00 00 03 CE 00 00
				/*Gamma*/
				39 01 00 00 00 00 A9 D0 12 05 20 1B 2C 28 3F 3D 4F 4F 66 66 6E 6E 76 76 80 80 88 88 95 95 3F 3F A2 A2 94 94 8B 8B 81 81 75 75 66 66 47 47 2D 2D 00 01 12 05 20 1B 2C 28 3F 3D 4f 4f 66 66 6e 6e 76 76 80 80 88 88 95 95 3F 3F A2 A2 94 94 8b 8b 81 81 75 75 66 66 47 47 2d 2d 00 01 12 05 20 1B 2C 28 3F 3D 4f 4f 66 66 6e 6e 76 76 80 80 88 88 95 95 3F 3F A2 A2 94 94 8b 8b 81 81 75 75 66 66 47 47 2d 2d 00 01 12 05 20 1B 2C 28 3F 3D 4f 4f 66 66 6e 6e 76 76 80 80 88 88 94 94 3F 3F A4 A4 95 95 8b 8b 81 81 75 75 66 66 47 47 2d 2d 00 01
				39 01 00 00 00 00 A9 D1 12 05 20 1B 2C 28 3F 3D 4F 4F 66 66 6E 6E 76 76 80 80 88 88 95 95 3F 3F A2 A2 94 94 8B 8B 81 81 75 75 66 66 47 47 2D 2D 00 01 12 05 20 1B 2C 28 3F 3D 4f 4f 66 66 6e 6e 76 76 80 80 88 88 95 95 3F 3F A2 A2 94 94 8b 8b 81 81 75 75 66 66 47 47 2d 2d 00 01 12 05 20 1B 2C 28 3F 3D 4f 4f 66 66 6e 6e 76 76 80 80 88 88 95 95 3F 3F A2 A2 94 94 8b 8b 81 81 75 75 66 66 47 47 2d 2d 00 01 12 05 20 1B 2C 28 3F 3D 4f 4f 66 66 6e 6e 76 76 80 80 88 88 94 94 3F 3F A4 A4 95 95 8b 8b 81 81 75 75 66 66 47 47 2d 2d 00 01
				39 01 00 00 00 00 A9 D2 12 05 20 1B 2C 28 3F 3D 4F 4F 66 66 6E 6E 76 76 80 80 88 88 95 95 3F 3F A2 A2 94 94 8B 8B 81 81 75 75 66 66 47 47 2D 2D 00 01 12 05 20 1B 2C 28 3F 3D 4f 4f 66 66 6e 6e 76 76 80 80 88 88 95 95 3F 3F A2 A2 94 94 8b 8b 81 81 75 75 66 66 47 47 2d 2d 00 01 12 05 20 1B 2C 28 3F 3D 4f 4f 66 66 6e 6e 76 76 80 80 88 88 95 95 3F 3F A2 A2 94 94 8b 8b 81 81 75 75 66 66 47 47 2d 2d 00 01 12 05 20 1B 2C 28 3F 3D 4f 4f 66 66 6e 6e 76 76 80 80 88 88 94 94 3F 3F A4 A4 95 95 8b 8b 81 81 75 75 66 66 47 47 2d 2d 00 01
				/* MPLUS Control */
				39 01 00 00 00 00 05 D3 12 01 00 00
				/*Mplus Setting*/
				39 01 00 00 00 00 96 D4 DC 5F 9C BE 39 39 39 47 48 48 48 3A 00 03 6D 80 00 00 8C 66 00 00 8C 66 00 00 8C 66 00 0A 48 80 00 0A 48 80 00 0A 48 80 00 0A 48 80 20 0A 14 0A 18 00 23 9E 23 9E 23 9E 01 01 01 01 04 04 04 04 01 00 02 80 00 10 00 10 00 10 13 9E 13 9E 13 9E 13 9E 05 05 05 05 05 05 05 05 23 9E FF FF 16 66 18 00 16 66 10 00 FF 01 00 02 00 03 00 04 00 05 00 06 00 07 00 08 00 09 00 0A 00 0B 00 0C 00 0D 00 0E 00 0F 00 1B 25 DC 18 00 20 00 1C E1 00 FF E0 C8 C8 41 8F
				/*Notch Up Gradation*/
				39 01 00 00 00 00 21 AD 01 02 03 04 05 06 06 06 06 06 06 06 06 06 06 06 20 40 60 90 C0 F0 FF FF FF FF FF FF FF FF FF FF
				/*Notch Down Gradation*/
				39 01 00 00 00 00 21 AE 01 02 03 04 05 06 06 06 06 06 06 06 06 06 06 06 20 40 60 90 C0 F0 FF FF FF FF FF FF FF FF FF FF
				/*GIP Setting*/
				39 01 00 00 00 00 1B E5 0B 0A 0C 00 02 04 06 08 0F 1B 02 1A 1A 0B 0A 0C 01 03 05 07 09 10 1B 03 1A 1A
				/*Mux Setting*/
				39 01 00 00 00 00 11 E6 11 12 13 14 15 16 17 18 11 12 13 14 15 16 17 18
				/*Test1*/
				39 01 00 00 00 00 07 ED 21 49 00 00 00 00
				/*BLU Control*/
				15 01 00 00 00 00 02 55 81
				/*Gamma Correction*/
				39 01 00 00 00 00 02 F5 00
				39 01 00 00 00 00 11 F6 40 40 40 40 40 40 40 40 00 00 00 00 00 00 00 00
				39 01 00 00 00 00 11 F7 40 40 40 40 40 40 40 40 00 00 00 00 00 00 00 00
				39 01 00 00 00 00 11 F8 40 40 40 40 40 40 40 40 00 00 00 00 00 00 00 00
				/*Sharpness*/
				39 01 00 00 00 00 06 F3 00 01 00 0D 00
				39 01 00 00 00 00 0E F4 00 00 40 83 C5 00 01 00 00 00 00 00 00
				39 01 00 00 00 00 18 FB 20 40 60 80 a0 c0 e0 13 18 18 18 16 0D 0D 00 C7 CF D8 E1 EA F3 F9 FF
				/*BLU PWM Control*/
				39 01 00 00 00 00 0E FC 13 70 D0 26 30 7C 02 FF 12 22 22 10 00
				/* Normal Display mode on */
				05 01 00 00 00 00 01 13
				/* Sleep Out + min 120ms */
				05 01 00 00 80 00 01 11
				/*GIP Setting - APO high*/
				39 01 00 00 64 00 1B E5 0B 0A 1C 00 02 04 06 08 0F 1B 02 1A 1A 0B 0A 1C 01 03 05 07 09 10 1B 03 1A 1A
				/*Power Sequence Option Configuration*/
				39 01 00 00 00 00 06 C9 05 5D 03 04 00
				/*GIP Setting*/
				39 01 00 00 00 00 1B E5 0B 0A 0C 00 02 04 06 08 0F 1B 02 1A 1A 0B 0A 0C 01 03 05 07 09 10 1B 03 1A 1A
				/*Black Frame Setting*/
				39 01 00 00 00 00 03 BD 01 05
				05 01 00 00 05 00 01 29
			];
		};
	};
};
&dsi_sw49410_dsc_1440_3120_cmd {
	qcom,mdss-dsi-display-timings {
		timing@0{
			qcom,mdss-dsi-on-command = [
				/* TE On */
				15 01 00 00 00 00 02 35 00
				/* Page Address Set */
				39 01 00 00 00 00 05 2B 00 00 0C 2F
				/* BLU Control */
				15 01 00 00 00 00 02 51 FF
				15 01 00 00 00 00 02 53 2C
				15 01 00 00 00 00 02 5E 00
				15 01 00 00 00 00 02 55 81
				/*Manufacturer protection*/
				15 01 00 00 00 00 02 B0 AC
				/*Source Control*/
				39 01 00 00 00 00 09 B3 04 04 28 08 5A 12 23 02
				/*Gate & Mux Control*/
				39 01 00 00 00 00 20 B4 11 04 02 02 02 02 02 01 01 01 01 01 01 D0 E4 E4 E4 93 4E 39 0A 10 18 25 24 00 00 00 00 00 00
				/*Sync Setup*/
				39 01 00 00 00 00 09 B5 2E 0F 10 C0 00 10 C0 00
				/*Panel Setting*/
				39 01 00 00 00 00 06 B6 03 05 0B B3 30
				/*Touch Timing Control*/
				39 01 00 00 00 00 20 B8 57 02 90 40 5D D0 05 00 00 18 22 04 01 02 90 40 4C C0 04 00 00 18 22 04 01 08 00 3A 86 83 00
				/*Touch Source Setting*/
				39 01 00 00 00 00 06 B9 64 64 2A 3F EE
				/*DSC Configuration*/
				39 01 00 00 00 00 0C BA 3D 1F 01 FF 01 3C 1F 01 FF 01 00
				/*Low Rate Refresh Setting*/
				39 01 00 00 00 00 05 BC 00 00 00 10
				/*Black Frame Setting*/
				39 01 00 00 00 00 03 BD 00 00
				/* U2 Corner Down */
				39 01 00 00 00 00 03 BF 4F 02
				/*Internal Oscillator Setting*/
				39 01 00 00 00 00 0B C0 00 04 18 07 11 11 3C 00 0A 0A
				/*Power Control1*/
				39 01 00 00 00 00 07 C1 01 00 F0 C2 CF 0C
				/*Power Control2*/
				39 01 00 00 00 00 09 C2 CC 44 44 00 22 26 21 00
				/*Power Control3*/
				39 01 00 00 00 00 13 C3 92 11 09 09 11 CC 02 02 A4 A4 02 A2 38 28 14 46 3C C0
				/*Vcom Setting*/
				39 01 00 00 00 00 03 C4 2F 00
				/*Power Sequence Option Configuration*/
				39 01 00 00 00 00 06 C9 05 5D 03 04 00
				/*Abrupt Power Off Control*/
				39 01 00 00 00 00 03 CA 9B 10
				/*LFD Control*/
				39 01 00 00 00 00 06 CB F3 90 3D 30 CC
				/*Tail TFT Setting*/
				39 01 00 00 00 00 06 CC 00 40 50 90 41
				/*U2 Option*/
				39 01 00 00 00 00 03 CE 00 00
				/*Gamma*/
				39 01 00 00 00 00 A9 D0 01 01 1e 1e 2A 2A 3d 3d 50 50 65 65 6d 6d 73 73 7c 7c 84 84 91 91 3F 3F A7 A7 98 98 8f 8f 86 86 7a 7a 6a 6a 4c 4c 33 33 01 01 01 01 1E 1E 2A 2A 3d 3d 50 50 65 65 6d 6d 73 73 7c 7c 84 84 91 91 3F 3F A7 A7 98 98 8f 8f 86 86 7a 7a 6a 6a 4c 4c 33 33 01 01 01 01 1e 1e 2A 2A 3d 3d 50 50 65 65 6d 6d 73 73 7c 7c 84 84 91 91 3F 3F A7 A7 98 98 8f 8f 86 86 7a 7a 6a 6a 4c 4c 33 33 01 01 01 01 1e 1e 2A 2A 3d 3d 50 50 65 65 6d 6d 73 73 7c 7c 84 84 90 90 3F 3F A8 A8 99 99 90 90 88 88 7c 7c 6d 6d 4f 4f 36 36 01 01
				39 01 00 00 00 00 A9 D1 01 01 1e 1e 2A 2A 3d 3d 50 50 65 65 6d 6d 73 73 7c 7c 84 84 91 91 3F 3F A7 A7 98 98 8f 8f 86 86 7a 7a 6a 6a 4c 4c 33 33 01 01 01 01 1E 1E 2A 2A 3d 3d 50 50 65 65 6d 6d 73 73 7c 7c 84 84 91 91 3F 3F A7 A7 98 98 8f 8f 86 86 7a 7a 6a 6a 4c 4c 33 33 01 01 01 01 1e 1e 2A 2A 3d 3d 50 50 65 65 6d 6d 73 73 7c 7c 84 84 91 91 3F 3F A7 A7 98 98 8f 8f 86 86 7a 7a 6a 6a 4c 4c 33 33 01 01 01 01 1e 1e 2A 2A 3d 3d 50 50 65 65 6d 6d 73 73 7c 7c 84 84 90 90 3F 3F A8 A8 99 99 90 90 88 88 7c 7c 6d 6d 4f 4f 36 36 01 01
				39 01 00 00 00 00 A9 D2 01 01 1e 1e 2A 2A 3d 3d 50 50 65 65 6d 6d 73 73 7c 7c 84 84 91 91 3F 3F A7 A7 98 98 8f 8f 86 86 7a 7a 6a 6a 4c 4c 33 33 01 01 01 01 1E 1E 2A 2A 3d 3d 50 50 65 65 6d 6d 73 73 7c 7c 84 84 91 91 3F 3F A7 A7 98 98 8f 8f 86 86 7a 7a 6a 6a 4c 4c 33 33 01 01 01 01 1e 1e 2A 2A 3d 3d 50 50 65 65 6d 6d 73 73 7c 7c 84 84 91 91 3F 3F A7 A7 98 98 8f 8f 86 86 7a 7a 6a 6a 4c 4c 33 33 01 01 01 01 1e 1e 2A 2A 3d 3d 50 50 65 65 6d 6d 73 73 7c 7c 84 84 90 90 3F 3F A8 A8 99 99 90 90 88 88 7c 7c 6d 6d 4f 4f 36 36 01 01
				/* MPLUS Control */
				39 01 00 00 00 00 05 D3 12 01 00 00
				/*Mplus Setting*/
				39 01 00 00 00 00 96 D4 DC 5F 9C BE 39 39 39 47 48 48 48 3A 00 03 6D 80 00 00 8C 66 00 00 8C 66 00 00 8C 66 00 0A 48 80 00 0A 48 80 00 0A 48 80 00 0A 48 80 20 0A 14 0A 18 00 23 9E 23 9E 23 9E 01 01 01 01 04 04 04 04 01 00 02 80 00 10 00 10 00 10 13 9E 13 9E 13 9E 13 9E 05 05 05 05 05 05 05 05 23 9E FF FF 16 66 18 00 16 66 10 00 FF 01 00 02 00 03 00 04 00 05 00 06 00 07 00 08 00 09 00 0A 00 0B 00 0C 00 0D 00 0E 00 0F 00 1B 25 DC 18 00 20 00 1C E1 00 FF E0 C8 C8 41 8F
				/*Notch Up Gradation*/
				39 01 00 00 00 00 21 AD 01 02 03 04 05 06 06 06 06 06 06 06 06 06 06 06 20 40 60 90 C0 F0 FF FF FF FF FF FF FF FF FF FF
				/*Notch Down Gradation*/
				39 01 00 00 00 00 21 AE 01 02 03 04 05 06 06 06 06 06 06 06 06 06 06 06 20 40 60 90 C0 F0 FF FF FF FF FF FF FF FF FF FF
				/*GIP Setting*/
				39 01 00 00 00 00 1B E5 0B 0A 0C 00 02 04 06 08 0F 1B 02 1A 1A 0B 0A 0C 01 03 05 07 09 10 1B 03 1A 1A
				/*Mux Setting*/
				39 01 00 00 00 00 11 E6 11 12 13 14 15 16 17 18 11 12 13 14 15 16 17 18
				/*Test1*/
				39 01 00 00 00 00 07 ED 21 49 00 00 00 00
				/*BLU Control*/
				15 01 00 00 00 00 02 55 81
				/*Sharpness*/
				39 01 00 00 00 00 06 F3 00 01 00 0D 00
				39 01 00 00 00 00 0E F4 00 00 40 83 C5 00 01 00 00 00 00 00 00
				39 01 00 00 00 00 18 FB 20 40 60 80 a0 c0 e0 13 18 18 18 16 0D 0D 00 C7 CF D8 E1 EA F3 F9 FF
				/*Gamma Correction*/
				39 01 00 00 00 00 02 F5 00
				39 01 00 00 00 00 11 F6 40 40 40 40 40 40 40 40 00 00 00 00 00 00 00 00
				39 01 00 00 00 00 11 F7 40 40 40 40 40 40 40 40 00 00 00 00 00 00 00 00
				39 01 00 00 00 00 11 F8 40 40 40 40 40 40 40 40 00 00 00 00 00 00 00 00
				/*BLU PWM Control*/
				39 01 00 00 00 00 0E FC 13 70 D0 26 30 7C 02 FF 12 22 22 10 00
				/* Normal Display mode on */
				05 01 00 00 00 00 01 13
				/* Sleep Out + min 120ms */
				05 01 00 00 80 00 01 11
				/*Black Frame Setting*/
				39 01 00 00 00 00 03 BD 01 05
				05 01 00 00 05 00 01 29
			];

			qcom,mdss-dsi-on-command-with-apo = [
				/* TE On */
				15 01 00 00 00 00 02 35 00
				/* Page Address Set */
				39 01 00 00 00 00 05 2B 00 00 0C 2F
				/* BLU Control */
				15 01 00 00 00 00 02 51 FF
				15 01 00 00 00 00 02 53 2C
				15 01 00 00 00 00 02 5E 00
				15 01 00 00 00 00 02 55 81
				/*Manufacturer protection*/
				15 01 00 00 00 00 02 B0 AC
				/*Source Control*/
				39 01 00 00 00 00 09 B3 04 04 28 08 5A 12 23 02
				/*Gate & Mux Control*/
				39 01 00 00 00 00 20 B4 11 04 02 02 02 02 02 01 01 01 01 01 01 D0 E4 E4 E4 93 4E 39 0A 10 18 25 24 00 00 00 00 00 00
				/*Sync Setup*/
				39 01 00 00 00 00 09 B5 2E 0F 10 C0 00 10 C0 00
				/*Panel Setting*/
				39 01 00 00 00 00 06 B6 03 05 0B B3 30
				/*Touch Timing Control*/
				39 01 00 00 00 00 20 B8 57 02 90 40 5D D0 05 00 00 18 22 04 01 02 90 40 4C C0 04 00 00 18 22 04 01 08 00 3A 86 83 00
				/*Touch Source Setting*/
				39 01 00 00 00 00 06 B9 64 64 2A 3F EE
				/*DSC Configuration*/
				39 01 00 00 00 00 0C BA 3D 1F 01 FF 01 3C 1F 01 FF 01 00
				/*Low Rate Refresh Setting*/
				39 01 00 00 00 00 05 BC 00 00 00 10
				/*Black Frame Setting*/
				39 01 00 00 00 00 03 BD 00 00
				/* U2 Corner Down */
				39 01 00 00 00 00 03 BF 4F 02
				/*Internal Oscillator Setting*/
				39 01 00 00 00 00 0B C0 00 04 18 07 11 11 3C 00 0A 0A
				/*Power Control1*/
				39 01 00 00 00 00 07 C1 01 00 F0 C2 CF 0C
				/*Power Control2*/
				39 01 00 00 00 00 09 C2 CC 44 44 00 22 26 21 00
				/*Power Control3*/
				39 01 00 00 00 00 13 C3 92 11 09 09 11 CC 02 02 A4 A4 02 A2 38 28 14 46 3C C0
				/*Vcom Setting*/
				39 01 00 00 00 00 03 C4 2F 00
				/*Power Sequence Option Configuration - source & vcom GND*/
				39 01 00 00 00 00 06 C9 01 54 03 04 00
				/*Abrupt Power Off Control*/
				39 01 00 00 00 00 03 CA 9B 10
				/*LFD Control*/
				39 01 00 00 00 00 06 CB F3 90 3D 30 CC
				/*Tail TFT Setting*/
				39 01 00 00 00 00 06 CC 00 40 50 90 41
				/*U2 Option*/
				39 01 00 00 00 00 03 CE 00 00
				/*Gamma*/
				39 01 00 00 00 00 A9 D0 01 01 1e 1e 2A 2A 3d 3d 50 50 65 65 6d 6d 73 73 7c 7c 84 84 91 91 3F 3F A7 A7 98 98 8f 8f 86 86 7a 7a 6a 6a 4c 4c 33 33 01 01 01 01 1E 1E 2A 2A 3d 3d 50 50 65 65 6d 6d 73 73 7c 7c 84 84 91 91 3F 3F A7 A7 98 98 8f 8f 86 86 7a 7a 6a 6a 4c 4c 33 33 01 01 01 01 1e 1e 2A 2A 3d 3d 50 50 65 65 6d 6d 73 73 7c 7c 84 84 91 91 3F 3F A7 A7 98 98 8f 8f 86 86 7a 7a 6a 6a 4c 4c 33 33 01 01 01 01 1e 1e 2A 2A 3d 3d 50 50 65 65 6d 6d 73 73 7c 7c 84 84 90 90 3F 3F A8 A8 99 99 90 90 88 88 7c 7c 6d 6d 4f 4f 36 36 01 01
				39 01 00 00 00 00 A9 D1 01 01 1e 1e 2A 2A 3d 3d 50 50 65 65 6d 6d 73 73 7c 7c 84 84 91 91 3F 3F A7 A7 98 98 8f 8f 86 86 7a 7a 6a 6a 4c 4c 33 33 01 01 01 01 1E 1E 2A 2A 3d 3d 50 50 65 65 6d 6d 73 73 7c 7c 84 84 91 91 3F 3F A7 A7 98 98 8f 8f 86 86 7a 7a 6a 6a 4c 4c 33 33 01 01 01 01 1e 1e 2A 2A 3d 3d 50 50 65 65 6d 6d 73 73 7c 7c 84 84 91 91 3F 3F A7 A7 98 98 8f 8f 86 86 7a 7a 6a 6a 4c 4c 33 33 01 01 01 01 1e 1e 2A 2A 3d 3d 50 50 65 65 6d 6d 73 73 7c 7c 84 84 90 90 3F 3F A8 A8 99 99 90 90 88 88 7c 7c 6d 6d 4f 4f 36 36 01 01
				39 01 00 00 00 00 A9 D2 01 01 1e 1e 2A 2A 3d 3d 50 50 65 65 6d 6d 73 73 7c 7c 84 84 91 91 3F 3F A7 A7 98 98 8f 8f 86 86 7a 7a 6a 6a 4c 4c 33 33 01 01 01 01 1E 1E 2A 2A 3d 3d 50 50 65 65 6d 6d 73 73 7c 7c 84 84 91 91 3F 3F A7 A7 98 98 8f 8f 86 86 7a 7a 6a 6a 4c 4c 33 33 01 01 01 01 1e 1e 2A 2A 3d 3d 50 50 65 65 6d 6d 73 73 7c 7c 84 84 91 91 3F 3F A7 A7 98 98 8f 8f 86 86 7a 7a 6a 6a 4c 4c 33 33 01 01 01 01 1e 1e 2A 2A 3d 3d 50 50 65 65 6d 6d 73 73 7c 7c 84 84 90 90 3F 3F A8 A8 99 99 90 90 88 88 7c 7c 6d 6d 4f 4f 36 36 01 01
				/* MPLUS Control */
				39 01 00 00 00 00 05 D3 12 01 00 00
				/*Mplus Setting*/
				39 01 00 00 00 00 96 D4 DC 5F 9C BE 39 39 39 47 48 48 48 3A 00 03 6D 80 00 00 8C 66 00 00 8C 66 00 00 8C 66 00 0A 48 80 00 0A 48 80 00 0A 48 80 00 0A 48 80 20 0A 14 0A 18 00 23 9E 23 9E 23 9E 01 01 01 01 04 04 04 04 01 00 02 80 00 10 00 10 00 10 13 9E 13 9E 13 9E 13 9E 05 05 05 05 05 05 05 05 23 9E FF FF 16 66 18 00 16 66 10 00 FF 01 00 02 00 03 00 04 00 05 00 06 00 07 00 08 00 09 00 0A 00 0B 00 0C 00 0D 00 0E 00 0F 00 1B 25 DC 18 00 20 00 1C E1 00 FF E0 C8 C8 41 8F
				/*Notch Up Gradation*/
				39 01 00 00 00 00 21 AD 01 02 03 04 05 06 06 06 06 06 06 06 06 06 06 06 20 40 60 90 C0 F0 FF FF FF FF FF FF FF FF FF FF
				/*Notch Down Gradation*/
				39 01 00 00 00 00 21 AE 01 02 03 04 05 06 06 06 06 06 06 06 06 06 06 06 20 40 60 90 C0 F0 FF FF FF FF FF FF FF FF FF FF
				/*GIP Setting*/
				39 01 00 00 00 00 1B E5 0B 0A 0C 00 02 04 06 08 0F 1B 02 1A 1A 0B 0A 0C 01 03 05 07 09 10 1B 03 1A 1A
				/*Mux Setting*/
				39 01 00 00 00 00 11 E6 11 12 13 14 15 16 17 18 11 12 13 14 15 16 17 18
				/*Test1*/
				39 01 00 00 00 00 07 ED 21 49 00 00 00 00
				/*BLU Control*/
				15 01 00 00 00 00 02 55 81
				/*Sharpness*/
				39 01 00 00 00 00 06 F3 00 01 00 0D 00
				39 01 00 00 00 00 0E F4 00 00 40 83 C5 00 01 00 00 00 00 00 00
				39 01 00 00 00 00 18 FB 20 40 60 80 a0 c0 e0 13 18 18 18 16 0D 0D 00 C7 CF D8 E1 EA F3 F9 FF
				/*Gamma Correction*/
				39 01 00 00 00 00 02 F5 00
				39 01 00 00 00 00 11 F6 40 40 40 40 40 40 40 40 00 00 00 00 00 00 00 00
				39 01 00 00 00 00 11 F7 40 40 40 40 40 40 40 40 00 00 00 00 00 00 00 00
				39 01 00 00 00 00 11 F8 40 40 40 40 40 40 40 40 00 00 00 00 00 00 00 00
				/*BLU PWM Control*/
				39 01 00 00 00 00 0E FC 13 70 D0 26 30 7C 02 FF 12 22 22 10 00
				/* Normal Display mode on */
				05 01 00 00 00 00 01 13
				/* Sleep Out + min 120ms */
				05 01 00 00 80 00 01 11
				/*GIP Setting - APO high*/
				39 01 00 00 64 00 1B E5 0B 0A 1C 00 02 04 06 08 0F 1B 02 1A 1A 0B 0A 1C 01 03 05 07 09 10 1B 03 1A 1A
				/*Power Sequence Option Configuration*/
				39 01 00 00 00 00 06 C9 05 5D 03 04 00
				/*GIP Setting*/
				39 01 00 00 00 00 1B E5 0B 0A 0C 00 02 04 06 08 0F 1B 02 1A 1A 0B 0A 0C 01 03 05 07 09 10 1B 03 1A 1A
				/*Black Frame Setting*/
				39 01 00 00 00 00 03 BD 01 05
				05 01 00 00 05 00 01 29
			];
		};
		timing@1{
			qcom,mdss-dsi-on-command = [
				/* TE On */
				15 01 00 00 00 00 02 35 00
				/* Page Address Set */
				39 01 00 00 00 00 05 2B 00 00 0C 2F
				/* BLU Control */
				15 01 00 00 00 00 02 51 FF
				15 01 00 00 00 00 02 53 2C
				15 01 00 00 00 00 02 5E 00
				15 01 00 00 00 00 02 55 81
				/*Manufacturer protection*/
				15 01 00 00 00 00 02 B0 AC
				/*Source Control*/
				39 01 00 00 00 00 09 B3 04 04 28 08 5A 12 23 02
				/*Gate & Mux Control*/
				39 01 00 00 00 00 20 B4 11 04 02 02 02 02 02 01 01 01 01 01 01 D0 E4 E4 E4 93 4E 39 0A 10 18 25 24 00 00 00 00 00 00
				/*Sync Setup*/
				39 01 00 00 00 00 09 B5 2E 0F 10 C0 00 10 C0 00
				/*Panel Setting*/
				39 01 00 00 00 00 06 B6 03 05 0B B3 30
				/*Touch Timing Control*/
				39 01 00 00 00 00 20 B8 57 02 90 40 5D D0 05 00 00 18 22 04 01 02 90 40 4C C0 04 00 00 18 22 04 01 08 00 3A 86 83 00
				/*Touch Source Setting*/
				39 01 00 00 00 00 06 B9 64 64 2A 3F EE
				/*DSC Configuration*/
				39 01 00 00 00 00 0C BA 3D 1F 01 FF 01 3C 1F 01 FF 01 00
				/*Low Rate Refresh Setting*/
				39 01 00 00 00 00 05 BC 00 00 00 10
				/*Black Frame Setting*/
				39 01 00 00 00 00 03 BD 00 00
				/* U2 Corner Down */
				39 01 00 00 00 00 03 BF 4F 02
				/*Internal Oscillator Setting*/
				39 01 00 00 00 00 0B C0 00 04 18 07 11 11 3C 00 0A 0A
				/*Power Control1*/
				39 01 00 00 00 00 07 C1 01 00 F0 C2 CF 0C
				/*Power Control2*/
				39 01 00 00 00 00 09 C2 CC 44 44 00 22 26 21 00
				/*Power Control3*/
				39 01 00 00 00 00 13 C3 92 11 09 09 11 CC 02 02 A4 A4 02 A2 38 28 14 46 3C C0
				/*Vcom Setting*/
				39 01 00 00 00 00 03 C4 2F 00
				/*Power Sequence Option Configuration*/
				39 01 00 00 00 00 06 C9 05 5D 03 04 00
				/*Abrupt Power Off Control*/
				39 01 00 00 00 00 03 CA 9B 10
				/*LFD Control*/
				39 01 00 00 00 00 06 CB F3 90 3D 30 CC
				/*Tail TFT Setting*/
				39 01 00 00 00 00 06 CC 00 40 50 90 41
				/*U2 Option*/
				39 01 00 00 00 00 03 CE 00 00
				/*Gamma*/
				39 01 00 00 00 00 A9 D0 01 01 1e 1e 2A 2A 3d 3d 50 50 65 65 6d 6d 73 73 7c 7c 84 84 91 91 3F 3F A7 A7 98 98 8f 8f 86 86 7a 7a 6a 6a 4c 4c 33 33 01 01 01 01 1E 1E 2A 2A 3d 3d 50 50 65 65 6d 6d 73 73 7c 7c 84 84 91 91 3F 3F A7 A7 98 98 8f 8f 86 86 7a 7a 6a 6a 4c 4c 33 33 01 01 01 01 1e 1e 2A 2A 3d 3d 50 50 65 65 6d 6d 73 73 7c 7c 84 84 91 91 3F 3F A7 A7 98 98 8f 8f 86 86 7a 7a 6a 6a 4c 4c 33 33 01 01 01 01 1e 1e 2A 2A 3d 3d 50 50 65 65 6d 6d 73 73 7c 7c 84 84 90 90 3F 3F A8 A8 99 99 90 90 88 88 7c 7c 6d 6d 4f 4f 36 36 01 01
				39 01 00 00 00 00 A9 D1 01 01 1e 1e 2A 2A 3d 3d 50 50 65 65 6d 6d 73 73 7c 7c 84 84 91 91 3F 3F A7 A7 98 98 8f 8f 86 86 7a 7a 6a 6a 4c 4c 33 33 01 01 01 01 1E 1E 2A 2A 3d 3d 50 50 65 65 6d 6d 73 73 7c 7c 84 84 91 91 3F 3F A7 A7 98 98 8f 8f 86 86 7a 7a 6a 6a 4c 4c 33 33 01 01 01 01 1e 1e 2A 2A 3d 3d 50 50 65 65 6d 6d 73 73 7c 7c 84 84 91 91 3F 3F A7 A7 98 98 8f 8f 86 86 7a 7a 6a 6a 4c 4c 33 33 01 01 01 01 1e 1e 2A 2A 3d 3d 50 50 65 65 6d 6d 73 73 7c 7c 84 84 90 90 3F 3F A8 A8 99 99 90 90 88 88 7c 7c 6d 6d 4f 4f 36 36 01 01
				39 01 00 00 00 00 A9 D2 01 01 1e 1e 2A 2A 3d 3d 50 50 65 65 6d 6d 73 73 7c 7c 84 84 91 91 3F 3F A7 A7 98 98 8f 8f 86 86 7a 7a 6a 6a 4c 4c 33 33 01 01 01 01 1E 1E 2A 2A 3d 3d 50 50 65 65 6d 6d 73 73 7c 7c 84 84 91 91 3F 3F A7 A7 98 98 8f 8f 86 86 7a 7a 6a 6a 4c 4c 33 33 01 01 01 01 1e 1e 2A 2A 3d 3d 50 50 65 65 6d 6d 73 73 7c 7c 84 84 91 91 3F 3F A7 A7 98 98 8f 8f 86 86 7a 7a 6a 6a 4c 4c 33 33 01 01 01 01 1e 1e 2A 2A 3d 3d 50 50 65 65 6d 6d 73 73 7c 7c 84 84 90 90 3F 3F A8 A8 99 99 90 90 88 88 7c 7c 6d 6d 4f 4f 36 36 01 01
				/* MPLUS Control */
				39 01 00 00 00 00 05 D3 12 01 00 00
				/*Mplus Setting*/
				39 01 00 00 00 00 96 D4 DC 5F 9C BE 39 39 39 47 48 48 48 3A 00 03 6D 80 00 00 8C 66 00 00 8C 66 00 00 8C 66 00 0A 48 80 00 0A 48 80 00 0A 48 80 00 0A 48 80 20 0A 14 0A 18 00 23 9E 23 9E 23 9E 01 01 01 01 04 04 04 04 01 00 02 80 00 10 00 10 00 10 13 9E 13 9E 13 9E 13 9E 05 05 05 05 05 05 05 05 23 9E FF FF 16 66 18 00 16 66 10 00 FF 01 00 02 00 03 00 04 00 05 00 06 00 07 00 08 00 09 00 0A 00 0B 00 0C 00 0D 00 0E 00 0F 00 1B 25 DC 18 00 20 00 1C E1 00 FF E0 C8 C8 41 8F
				/*Notch Up Gradation*/
				39 01 00 00 00 00 21 AD 01 02 03 04 05 06 06 06 06 06 06 06 06 06 06 06 20 40 60 90 C0 F0 FF FF FF FF FF FF FF FF FF FF
				/*Notch Down Gradation*/
				39 01 00 00 00 00 21 AE 01 02 03 04 05 06 06 06 06 06 06 06 06 06 06 06 20 40 60 90 C0 F0 FF FF FF FF FF FF FF FF FF FF
				/*GIP Setting*/
				39 01 00 00 00 00 1B E5 0B 0A 0C 00 02 04 06 08 0F 1B 02 1A 1A 0B 0A 0C 01 03 05 07 09 10 1B 03 1A 1A
				/*Mux Setting*/
				39 01 00 00 00 00 11 E6 11 12 13 14 15 16 17 18 11 12 13 14 15 16 17 18
				/*Test1*/
				39 01 00 00 00 00 07 ED 21 49 00 00 00 00
				/*BLU Control*/
				15 01 00 00 00 00 02 55 81
				/*Sharpness*/
				39 01 00 00 00 00 06 F3 00 01 00 0D 00
				39 01 00 00 00 00 0E F4 00 00 40 83 C5 00 01 00 00 00 00 00 00
				39 01 00 00 00 00 18 FB 20 40 60 80 a0 c0 e0 13 18 18 18 16 0D 0D 00 C7 CF D8 E1 EA F3 F9 FF
				/*Gamma Correction*/
				39 01 00 00 00 00 02 F5 00
				39 01 00 00 00 00 11 F6 40 40 40 40 40 40 40 40 00 00 00 00 00 00 00 00
				39 01 00 00 00 00 11 F7 40 40 40 40 40 40 40 40 00 00 00 00 00 00 00 00
				39 01 00 00 00 00 11 F8 40 40 40 40 40 40 40 40 00 00 00 00 00 00 00 00
				/*BLU PWM Control*/
				39 01 00 00 00 00 0E FC 13 70 D0 26 30 7C 02 FF 12 22 22 10 00
				/* Normal Display mode on */
				05 01 00 00 00 00 01 13
				/* Sleep Out + min 120ms */
				05 01 00 00 80 00 01 11
				/*Black Frame Setting*/
				39 01 00 00 00 00 03 BD 01 05
				05 01 00 00 05 00 01 29
			];

			qcom,mdss-dsi-on-command-with-apo = [
				/* TE On */
				15 01 00 00 00 00 02 35 00
				/* Page Address Set */
				39 01 00 00 00 00 05 2B 00 00 0C 2F
				/* BLU Control */
				15 01 00 00 00 00 02 51 FF
				15 01 00 00 00 00 02 53 2C
				15 01 00 00 00 00 02 5E 00
				15 01 00 00 00 00 02 55 81
				/*Manufacturer protection*/
				15 01 00 00 00 00 02 B0 AC
				/*Source Control*/
				39 01 00 00 00 00 09 B3 04 04 28 08 5A 12 23 02
				/*Gate & Mux Control*/
				39 01 00 00 00 00 20 B4 11 04 02 02 02 02 02 01 01 01 01 01 01 D0 E4 E4 E4 93 4E 39 0A 10 18 25 24 00 00 00 00 00 00
				/*Sync Setup*/
				39 01 00 00 00 00 09 B5 2E 0F 10 C0 00 10 C0 00
				/*Panel Setting*/
				39 01 00 00 00 00 06 B6 03 05 0B B3 30
				/*Touch Timing Control*/
				39 01 00 00 00 00 20 B8 57 02 90 40 5D D0 05 00 00 18 22 04 01 02 90 40 4C C0 04 00 00 18 22 04 01 08 00 3A 86 83 00
				/*Touch Source Setting*/
				39 01 00 00 00 00 06 B9 64 64 2A 3F EE
				/*DSC Configuration*/
				39 01 00 00 00 00 0C BA 3D 1F 01 FF 01 3C 1F 01 FF 01 00
				/*Low Rate Refresh Setting*/
				39 01 00 00 00 00 05 BC 00 00 00 10
				/*Black Frame Setting*/
				39 01 00 00 00 00 03 BD 00 00
				/* U2 Corner Down */
				39 01 00 00 00 00 03 BF 4F 02
				/*Internal Oscillator Setting*/
				39 01 00 00 00 00 0B C0 00 04 18 07 11 11 3C 00 0A 0A
				/*Power Control1*/
				39 01 00 00 00 00 07 C1 01 00 F0 C2 CF 0C
				/*Power Control2*/
				39 01 00 00 00 00 09 C2 CC 44 44 00 22 26 21 00
				/*Power Control3*/
				39 01 00 00 00 00 13 C3 92 11 09 09 11 CC 02 02 A4 A4 02 A2 38 28 14 46 3C C0
				/*Vcom Setting*/
				39 01 00 00 00 00 03 C4 2F 00
				/*Power Sequence Option Configuration - source & vcom GND*/
				39 01 00 00 00 00 06 C9 01 54 03 04 00
				/*Abrupt Power Off Control*/
				39 01 00 00 00 00 03 CA 9B 10
				/*LFD Control*/
				39 01 00 00 00 00 06 CB F3 90 3D 30 CC
				/*Tail TFT Setting*/
				39 01 00 00 00 00 06 CC 00 40 50 90 41
				/*U2 Option*/
				39 01 00 00 00 00 03 CE 00 00
				/*Gamma*/
				39 01 00 00 00 00 A9 D0 01 01 1e 1e 2A 2A 3d 3d 50 50 65 65 6d 6d 73 73 7c 7c 84 84 91 91 3F 3F A7 A7 98 98 8f 8f 86 86 7a 7a 6a 6a 4c 4c 33 33 01 01 01 01 1E 1E 2A 2A 3d 3d 50 50 65 65 6d 6d 73 73 7c 7c 84 84 91 91 3F 3F A7 A7 98 98 8f 8f 86 86 7a 7a 6a 6a 4c 4c 33 33 01 01 01 01 1e 1e 2A 2A 3d 3d 50 50 65 65 6d 6d 73 73 7c 7c 84 84 91 91 3F 3F A7 A7 98 98 8f 8f 86 86 7a 7a 6a 6a 4c 4c 33 33 01 01 01 01 1e 1e 2A 2A 3d 3d 50 50 65 65 6d 6d 73 73 7c 7c 84 84 90 90 3F 3F A8 A8 99 99 90 90 88 88 7c 7c 6d 6d 4f 4f 36 36 01 01
				39 01 00 00 00 00 A9 D1 01 01 1e 1e 2A 2A 3d 3d 50 50 65 65 6d 6d 73 73 7c 7c 84 84 91 91 3F 3F A7 A7 98 98 8f 8f 86 86 7a 7a 6a 6a 4c 4c 33 33 01 01 01 01 1E 1E 2A 2A 3d 3d 50 50 65 65 6d 6d 73 73 7c 7c 84 84 91 91 3F 3F A7 A7 98 98 8f 8f 86 86 7a 7a 6a 6a 4c 4c 33 33 01 01 01 01 1e 1e 2A 2A 3d 3d 50 50 65 65 6d 6d 73 73 7c 7c 84 84 91 91 3F 3F A7 A7 98 98 8f 8f 86 86 7a 7a 6a 6a 4c 4c 33 33 01 01 01 01 1e 1e 2A 2A 3d 3d 50 50 65 65 6d 6d 73 73 7c 7c 84 84 90 90 3F 3F A8 A8 99 99 90 90 88 88 7c 7c 6d 6d 4f 4f 36 36 01 01
				39 01 00 00 00 00 A9 D2 01 01 1e 1e 2A 2A 3d 3d 50 50 65 65 6d 6d 73 73 7c 7c 84 84 91 91 3F 3F A7 A7 98 98 8f 8f 86 86 7a 7a 6a 6a 4c 4c 33 33 01 01 01 01 1E 1E 2A 2A 3d 3d 50 50 65 65 6d 6d 73 73 7c 7c 84 84 91 91 3F 3F A7 A7 98 98 8f 8f 86 86 7a 7a 6a 6a 4c 4c 33 33 01 01 01 01 1e 1e 2A 2A 3d 3d 50 50 65 65 6d 6d 73 73 7c 7c 84 84 91 91 3F 3F A7 A7 98 98 8f 8f 86 86 7a 7a 6a 6a 4c 4c 33 33 01 01 01 01 1e 1e 2A 2A 3d 3d 50 50 65 65 6d 6d 73 73 7c 7c 84 84 90 90 3F 3F A8 A8 99 99 90 90 88 88 7c 7c 6d 6d 4f 4f 36 36 01 01
				/* MPLUS Control */
				39 01 00 00 00 00 05 D3 12 01 00 00
				/*Mplus Setting*/
				39 01 00 00 00 00 96 D4 DC 5F 9C BE 39 39 39 47 48 48 48 3A 00 03 6D 80 00 00 8C 66 00 00 8C 66 00 00 8C 66 00 0A 48 80 00 0A 48 80 00 0A 48 80 00 0A 48 80 20 0A 14 0A 18 00 23 9E 23 9E 23 9E 01 01 01 01 04 04 04 04 01 00 02 80 00 10 00 10 00 10 13 9E 13 9E 13 9E 13 9E 05 05 05 05 05 05 05 05 23 9E FF FF 16 66 18 00 16 66 10 00 FF 01 00 02 00 03 00 04 00 05 00 06 00 07 00 08 00 09 00 0A 00 0B 00 0C 00 0D 00 0E 00 0F 00 1B 25 DC 18 00 20 00 1C E1 00 FF E0 C8 C8 41 8F
				/*Notch Up Gradation*/
				39 01 00 00 00 00 21 AD 01 02 03 04 05 06 06 06 06 06 06 06 06 06 06 06 20 40 60 90 C0 F0 FF FF FF FF FF FF FF FF FF FF
				/*Notch Down Gradation*/
				39 01 00 00 00 00 21 AE 01 02 03 04 05 06 06 06 06 06 06 06 06 06 06 06 20 40 60 90 C0 F0 FF FF FF FF FF FF FF FF FF FF
				/*GIP Setting*/
				39 01 00 00 00 00 1B E5 0B 0A 0C 00 02 04 06 08 0F 1B 02 1A 1A 0B 0A 0C 01 03 05 07 09 10 1B 03 1A 1A
				/*Mux Setting*/
				39 01 00 00 00 00 11 E6 11 12 13 14 15 16 17 18 11 12 13 14 15 16 17 18
				/*Test1*/
				39 01 00 00 00 00 07 ED 21 49 00 00 00 00
				/*BLU Control*/
				15 01 00 00 00 00 02 55 81
				/*Sharpness*/
				39 01 00 00 00 00 06 F3 00 01 00 0D 00
				39 01 00 00 00 00 0E F4 00 00 40 83 C5 00 01 00 00 00 00 00 00
				39 01 00 00 00 00 18 FB 20 40 60 80 a0 c0 e0 13 18 18 18 16 0D 0D 00 C7 CF D8 E1 EA F3 F9 FF
				/*Gamma Correction*/
				39 01 00 00 00 00 02 F5 00
				39 01 00 00 00 00 11 F6 40 40 40 40 40 40 40 40 00 00 00 00 00 00 00 00
				39 01 00 00 00 00 11 F7 40 40 40 40 40 40 40 40 00 00 00 00 00 00 00 00
				39 01 00 00 00 00 11 F8 40 40 40 40 40 40 40 40 00 00 00 00 00 00 00 00
				/*BLU PWM Control*/
				39 01 00 00 00 00 0E FC 13 70 D0 26 30 7C 02 FF 12 22 22 10 00
				/* Normal Display mode on */
				05 01 00 00 00 00 01 13
				/* Sleep Out + min 120ms */
				05 01 00 00 80 00 01 11
				/*GIP Setting - APO high*/
				39 01 00 00 64 00 1B E5 0B 0A 1C 00 02 04 06 08 0F 1B 02 1A 1A 0B 0A 1C 01 03 05 07 09 10 1B 03 1A 1A
				/*Power Sequence Option Configuration*/
				39 01 00 00 00 00 06 C9 05 5D 03 04 00
				/*GIP Setting*/
				39 01 00 00 00 00 1B E5 0B 0A 0C 00 02 04 06 08 0F 1B 02 1A 1A 0B 0A 0C 01 03 05 07 09 10 1B 03 1A 1A
				/*Black Frame Setting*/
				39 01 00 00 00 00 03 BD 01 05
				05 01 00 00 05 00 01 29
			];
		};
		timing@2{
			qcom,mdss-dsi-on-command = [
				/* TE On */
				15 01 00 00 00 00 02 35 00
				/* Page Address Set */
				39 01 00 00 00 00 05 2B 00 00 0C 2F
				/* BLU Control */
				15 01 00 00 00 00 02 51 FF
				15 01 00 00 00 00 02 53 2C
				15 01 00 00 00 00 02 5E 00
				15 01 00 00 00 00 02 55 81
				/*Manufacturer protection*/
				15 01 00 00 00 00 02 B0 AC
				/*Source Control*/
				39 01 00 00 00 00 09 B3 04 04 28 08 5A 12 23 02
				/*Gate & Mux Control*/
				39 01 00 00 00 00 20 B4 11 04 02 02 02 02 02 01 01 01 01 01 01 D0 E4 E4 E4 93 4E 39 0A 10 18 25 24 00 00 00 00 00 00
				/*Sync Setup*/
				39 01 00 00 00 00 09 B5 2E 0F 10 C0 00 10 C0 00
				/*Panel Setting*/
				39 01 00 00 00 00 06 B6 03 05 0B B3 30
				/*Touch Timing Control*/
				39 01 00 00 00 00 20 B8 57 02 90 40 5D D0 05 00 00 18 22 04 01 02 90 40 4C C0 04 00 00 18 22 04 01 08 00 3A 86 83 00
				/*Touch Source Setting*/
				39 01 00 00 00 00 06 B9 64 64 2A 3F EE
				/*DSC Configuration*/
				39 01 00 00 00 00 0C BA 3D 1F 01 FF 01 3C 1F 01 FF 01 00
				/*Low Rate Refresh Setting*/
				39 01 00 00 00 00 05 BC 00 00 00 10
				/*Black Frame Setting*/
				39 01 00 00 00 00 03 BD 00 00
				/* U2 Corner Down */
				39 01 00 00 00 00 03 BF 4F 02
				/*Internal Oscillator Setting*/
				39 01 00 00 00 00 0B C0 00 04 18 07 11 11 3C 00 0A 0A
				/*Power Control1*/
				39 01 00 00 00 00 07 C1 01 00 F0 C2 CF 0C
				/*Power Control2*/
				39 01 00 00 00 00 09 C2 CC 44 44 00 22 26 21 00
				/*Power Control3*/
				39 01 00 00 00 00 13 C3 92 11 09 09 11 CC 02 02 A4 A4 02 A2 38 28 14 46 3C C0
				/*Vcom Setting*/
				39 01 00 00 00 00 03 C4 2F 00
				/*Power Sequence Option Configuration*/
				39 01 00 00 00 00 06 C9 05 5D 03 04 00
				/*Abrupt Power Off Control*/
				39 01 00 00 00 00 03 CA 9B 10
				/*LFD Control*/
				39 01 00 00 00 00 06 CB F3 90 3D 30 CC
				/*Tail TFT Setting*/
				39 01 00 00 00 00 06 CC 00 40 50 90 41
				/*U2 Option*/
				39 01 00 00 00 00 03 CE 00 00
				/*Gamma*/
				39 01 00 00 00 00 A9 D0 01 01 1e 1e 2A 2A 3d 3d 50 50 65 65 6d 6d 73 73 7c 7c 84 84 91 91 3F 3F A7 A7 98 98 8f 8f 86 86 7a 7a 6a 6a 4c 4c 33 33 01 01 01 01 1E 1E 2A 2A 3d 3d 50 50 65 65 6d 6d 73 73 7c 7c 84 84 91 91 3F 3F A7 A7 98 98 8f 8f 86 86 7a 7a 6a 6a 4c 4c 33 33 01 01 01 01 1e 1e 2A 2A 3d 3d 50 50 65 65 6d 6d 73 73 7c 7c 84 84 91 91 3F 3F A7 A7 98 98 8f 8f 86 86 7a 7a 6a 6a 4c 4c 33 33 01 01 01 01 1e 1e 2A 2A 3d 3d 50 50 65 65 6d 6d 73 73 7c 7c 84 84 90 90 3F 3F A8 A8 99 99 90 90 88 88 7c 7c 6d 6d 4f 4f 36 36 01 01
				39 01 00 00 00 00 A9 D1 01 01 1e 1e 2A 2A 3d 3d 50 50 65 65 6d 6d 73 73 7c 7c 84 84 91 91 3F 3F A7 A7 98 98 8f 8f 86 86 7a 7a 6a 6a 4c 4c 33 33 01 01 01 01 1E 1E 2A 2A 3d 3d 50 50 65 65 6d 6d 73 73 7c 7c 84 84 91 91 3F 3F A7 A7 98 98 8f 8f 86 86 7a 7a 6a 6a 4c 4c 33 33 01 01 01 01 1e 1e 2A 2A 3d 3d 50 50 65 65 6d 6d 73 73 7c 7c 84 84 91 91 3F 3F A7 A7 98 98 8f 8f 86 86 7a 7a 6a 6a 4c 4c 33 33 01 01 01 01 1e 1e 2A 2A 3d 3d 50 50 65 65 6d 6d 73 73 7c 7c 84 84 90 90 3F 3F A8 A8 99 99 90 90 88 88 7c 7c 6d 6d 4f 4f 36 36 01 01
				39 01 00 00 00 00 A9 D2 01 01 1e 1e 2A 2A 3d 3d 50 50 65 65 6d 6d 73 73 7c 7c 84 84 91 91 3F 3F A7 A7 98 98 8f 8f 86 86 7a 7a 6a 6a 4c 4c 33 33 01 01 01 01 1E 1E 2A 2A 3d 3d 50 50 65 65 6d 6d 73 73 7c 7c 84 84 91 91 3F 3F A7 A7 98 98 8f 8f 86 86 7a 7a 6a 6a 4c 4c 33 33 01 01 01 01 1e 1e 2A 2A 3d 3d 50 50 65 65 6d 6d 73 73 7c 7c 84 84 91 91 3F 3F A7 A7 98 98 8f 8f 86 86 7a 7a 6a 6a 4c 4c 33 33 01 01 01 01 1e 1e 2A 2A 3d 3d 50 50 65 65 6d 6d 73 73 7c 7c 84 84 90 90 3F 3F A8 A8 99 99 90 90 88 88 7c 7c 6d 6d 4f 4f 36 36 01 01
				/* MPLUS Control */
				39 01 00 00 00 00 05 D3 12 01 00 00
				/*Mplus Setting*/
				39 01 00 00 00 00 96 D4 DC 5F 9C BE 39 39 39 47 48 48 48 3A 00 03 6D 80 00 00 8C 66 00 00 8C 66 00 00 8C 66 00 0A 48 80 00 0A 48 80 00 0A 48 80 00 0A 48 80 20 0A 14 0A 18 00 23 9E 23 9E 23 9E 01 01 01 01 04 04 04 04 01 00 02 80 00 10 00 10 00 10 13 9E 13 9E 13 9E 13 9E 05 05 05 05 05 05 05 05 23 9E FF FF 16 66 18 00 16 66 10 00 FF 01 00 02 00 03 00 04 00 05 00 06 00 07 00 08 00 09 00 0A 00 0B 00 0C 00 0D 00 0E 00 0F 00 1B 25 DC 18 00 20 00 1C E1 00 FF E0 C8 C8 41 8F
				/*Notch Up Gradation*/
				39 01 00 00 00 00 21 AD 01 02 03 04 05 06 06 06 06 06 06 06 06 06 06 06 20 40 60 90 C0 F0 FF FF FF FF FF FF FF FF FF FF
				/*Notch Down Gradation*/
				39 01 00 00 00 00 21 AE 01 02 03 04 05 06 06 06 06 06 06 06 06 06 06 06 20 40 60 90 C0 F0 FF FF FF FF FF FF FF FF FF FF
				/*GIP Setting*/
				39 01 00 00 00 00 1B E5 0B 0A 0C 00 02 04 06 08 0F 1B 02 1A 1A 0B 0A 0C 01 03 05 07 09 10 1B 03 1A 1A
				/*Mux Setting*/
				39 01 00 00 00 00 11 E6 11 12 13 14 15 16 17 18 11 12 13 14 15 16 17 18
				/*Test1*/
				39 01 00 00 00 00 07 ED 21 49 00 00 00 00
				/*BLU Control*/
				15 01 00 00 00 00 02 55 81
				/*Gamma Correction*/
				39 01 00 00 00 00 02 F5 00
				39 01 00 00 00 00 11 F6 40 40 40 40 40 40 40 40 00 00 00 00 00 00 00 00
				39 01 00 00 00 00 11 F7 40 40 40 40 40 40 40 40 00 00 00 00 00 00 00 00
				39 01 00 00 00 00 11 F8 40 40 40 40 40 40 40 40 00 00 00 00 00 00 00 00
				/*Sharpness*/
				39 01 00 00 00 00 06 F3 00 01 00 0D 00
				39 01 00 00 00 00 0E F4 00 00 40 83 C5 00 01 00 00 00 00 00 00
				39 01 00 00 00 00 18 FB 20 40 60 80 a0 c0 e0 13 18 18 18 16 0D 0D 00 C7 CF D8 E1 EA F3 F9 FF
				/*BLU PWM Control*/
				39 01 00 00 00 00 0E FC 13 70 D0 26 30 7C 02 FF 12 22 22 10 00
				/* Normal Display mode on */
				05 01 00 00 00 00 01 13
				/* Sleep Out + min 120ms */
				05 01 00 00 80 00 01 11
				/*Black Frame Setting*/
				39 01 00 00 00 00 03 BD 01 05
				05 01 00 00 05 00 01 29
			];

			qcom,mdss-dsi-on-command-with-apo = [
				/* TE On */
				15 01 00 00 00 00 02 35 00
				/* Page Address Set */
				39 01 00 00 00 00 05 2B 00 00 0C 2F
				/* BLU Control */
				15 01 00 00 00 00 02 51 FF
				15 01 00 00 00 00 02 53 2C
				15 01 00 00 00 00 02 5E 00
				15 01 00 00 00 00 02 55 81
				/*Manufacturer protection*/
				15 01 00 00 00 00 02 B0 AC
				/*Source Control*/
				39 01 00 00 00 00 09 B3 04 04 28 08 5A 12 23 02
				/*Gate & Mux Control*/
				39 01 00 00 00 00 20 B4 11 04 02 02 02 02 02 01 01 01 01 01 01 D0 E4 E4 E4 93 4E 39 0A 10 18 25 24 00 00 00 00 00 00
				/*Sync Setup*/
				39 01 00 00 00 00 09 B5 2E 0F 10 C0 00 10 C0 00
				/*Panel Setting*/
				39 01 00 00 00 00 06 B6 03 05 0B B3 30
				/*Touch Timing Control*/
				39 01 00 00 00 00 20 B8 57 02 90 40 5D D0 05 00 00 18 22 04 01 02 90 40 4C C0 04 00 00 18 22 04 01 08 00 3A 86 83 00
				/*Touch Source Setting*/
				39 01 00 00 00 00 06 B9 64 64 2A 3F EE
				/*DSC Configuration*/
				39 01 00 00 00 00 0C BA 3D 1F 01 FF 01 3C 1F 01 FF 01 00
				/*Low Rate Refresh Setting*/
				39 01 00 00 00 00 05 BC 00 00 00 10
				/*Black Frame Setting*/
				39 01 00 00 00 00 03 BD 00 00
				/* U2 Corner Down */
				39 01 00 00 00 00 03 BF 4F 02
				/*Internal Oscillator Setting*/
				39 01 00 00 00 00 0B C0 00 04 18 07 11 11 3C 00 0A 0A
				/*Power Control1*/
				39 01 00 00 00 00 07 C1 01 00 F0 C2 CF 0C
				/*Power Control2*/
				39 01 00 00 00 00 09 C2 CC 44 44 00 22 26 21 00
				/*Power Control3*/
				39 01 00 00 00 00 13 C3 92 11 09 09 11 CC 02 02 A4 A4 02 A2 38 28 14 46 3C C0
				/*Vcom Setting*/
				39 01 00 00 00 00 03 C4 2F 00
				/*Power Sequence Option Configuration - source & vcom GND*/
				39 01 00 00 00 00 06 C9 01 54 03 04 00
				/*Abrupt Power Off Control*/
				39 01 00 00 00 00 03 CA 9B 10
				/*LFD Control*/
				39 01 00 00 00 00 06 CB F3 90 3D 30 CC
				/*Tail TFT Setting*/
				39 01 00 00 00 00 06 CC 00 40 50 90 41
				/*U2 Option*/
				39 01 00 00 00 00 03 CE 00 00
				/*Gamma*/
				39 01 00 00 00 00 A9 D0 01 01 1e 1e 2A 2A 3d 3d 50 50 65 65 6d 6d 73 73 7c 7c 84 84 91 91 3F 3F A7 A7 98 98 8f 8f 86 86 7a 7a 6a 6a 4c 4c 33 33 01 01 01 01 1E 1E 2A 2A 3d 3d 50 50 65 65 6d 6d 73 73 7c 7c 84 84 91 91 3F 3F A7 A7 98 98 8f 8f 86 86 7a 7a 6a 6a 4c 4c 33 33 01 01 01 01 1e 1e 2A 2A 3d 3d 50 50 65 65 6d 6d 73 73 7c 7c 84 84 91 91 3F 3F A7 A7 98 98 8f 8f 86 86 7a 7a 6a 6a 4c 4c 33 33 01 01 01 01 1e 1e 2A 2A 3d 3d 50 50 65 65 6d 6d 73 73 7c 7c 84 84 90 90 3F 3F A8 A8 99 99 90 90 88 88 7c 7c 6d 6d 4f 4f 36 36 01 01
				39 01 00 00 00 00 A9 D1 01 01 1e 1e 2A 2A 3d 3d 50 50 65 65 6d 6d 73 73 7c 7c 84 84 91 91 3F 3F A7 A7 98 98 8f 8f 86 86 7a 7a 6a 6a 4c 4c 33 33 01 01 01 01 1E 1E 2A 2A 3d 3d 50 50 65 65 6d 6d 73 73 7c 7c 84 84 91 91 3F 3F A7 A7 98 98 8f 8f 86 86 7a 7a 6a 6a 4c 4c 33 33 01 01 01 01 1e 1e 2A 2A 3d 3d 50 50 65 65 6d 6d 73 73 7c 7c 84 84 91 91 3F 3F A7 A7 98 98 8f 8f 86 86 7a 7a 6a 6a 4c 4c 33 33 01 01 01 01 1e 1e 2A 2A 3d 3d 50 50 65 65 6d 6d 73 73 7c 7c 84 84 90 90 3F 3F A8 A8 99 99 90 90 88 88 7c 7c 6d 6d 4f 4f 36 36 01 01
				39 01 00 00 00 00 A9 D2 01 01 1e 1e 2A 2A 3d 3d 50 50 65 65 6d 6d 73 73 7c 7c 84 84 91 91 3F 3F A7 A7 98 98 8f 8f 86 86 7a 7a 6a 6a 4c 4c 33 33 01 01 01 01 1E 1E 2A 2A 3d 3d 50 50 65 65 6d 6d 73 73 7c 7c 84 84 91 91 3F 3F A7 A7 98 98 8f 8f 86 86 7a 7a 6a 6a 4c 4c 33 33 01 01 01 01 1e 1e 2A 2A 3d 3d 50 50 65 65 6d 6d 73 73 7c 7c 84 84 91 91 3F 3F A7 A7 98 98 8f 8f 86 86 7a 7a 6a 6a 4c 4c 33 33 01 01 01 01 1e 1e 2A 2A 3d 3d 50 50 65 65 6d 6d 73 73 7c 7c 84 84 90 90 3F 3F A8 A8 99 99 90 90 88 88 7c 7c 6d 6d 4f 4f 36 36 01 01
				/* MPLUS Control */
				39 01 00 00 00 00 05 D3 12 01 00 00
				/*Mplus Setting*/
				39 01 00 00 00 00 96 D4 DC 5F 9C BE 39 39 39 47 48 48 48 3A 00 03 6D 80 00 00 8C 66 00 00 8C 66 00 00 8C 66 00 0A 48 80 00 0A 48 80 00 0A 48 80 00 0A 48 80 20 0A 14 0A 18 00 23 9E 23 9E 23 9E 01 01 01 01 04 04 04 04 01 00 02 80 00 10 00 10 00 10 13 9E 13 9E 13 9E 13 9E 05 05 05 05 05 05 05 05 23 9E FF FF 16 66 18 00 16 66 10 00 FF 01 00 02 00 03 00 04 00 05 00 06 00 07 00 08 00 09 00 0A 00 0B 00 0C 00 0D 00 0E 00 0F 00 1B 25 DC 18 00 20 00 1C E1 00 FF E0 C8 C8 41 8F
				/*Notch Up Gradation*/
				39 01 00 00 00 00 21 AD 01 02 03 04 05 06 06 06 06 06 06 06 06 06 06 06 20 40 60 90 C0 F0 FF FF FF FF FF FF FF FF FF FF
				/*Notch Down Gradation*/
				39 01 00 00 00 00 21 AE 01 02 03 04 05 06 06 06 06 06 06 06 06 06 06 06 20 40 60 90 C0 F0 FF FF FF FF FF FF FF FF FF FF
				/*GIP Setting*/
				39 01 00 00 00 00 1B E5 0B 0A 0C 00 02 04 06 08 0F 1B 02 1A 1A 0B 0A 0C 01 03 05 07 09 10 1B 03 1A 1A
				/*Mux Setting*/
				39 01 00 00 00 00 11 E6 11 12 13 14 15 16 17 18 11 12 13 14 15 16 17 18
				/*Test1*/
				39 01 00 00 00 00 07 ED 21 49 00 00 00 00
				/*BLU Control*/
				15 01 00 00 00 00 02 55 81
				/*Gamma Correction*/
				39 01 00 00 00 00 02 F5 00
				39 01 00 00 00 00 11 F6 40 40 40 40 40 40 40 40 00 00 00 00 00 00 00 00
				39 01 00 00 00 00 11 F7 40 40 40 40 40 40 40 40 00 00 00 00 00 00 00 00
				39 01 00 00 00 00 11 F8 40 40 40 40 40 40 40 40 00 00 00 00 00 00 00 00
				/*Sharpness*/
				39 01 00 00 00 00 06 F3 00 01 00 0D 00
				39 01 00 00 00 00 0E F4 00 00 40 83 C5 00 01 00 00 00 00 00 00
				39 01 00 00 00 00 18 FB 20 40 60 80 a0 c0 e0 13 18 18 18 16 0D 0D 00 C7 CF D8 E1 EA F3 F9 FF
				/*BLU PWM Control*/
				39 01 00 00 00 00 0E FC 13 70 D0 26 30 7C 02 FF 12 22 22 10 00
				/* Normal Display mode on */
				05 01 00 00 00 00 01 13
				/* Sleep Out + min 120ms */
				05 01 00 00 80 00 01 11
				/*GIP Setting - APO high*/
				39 01 00 00 64 00 1B E5 0B 0A 1C 00 02 04 06 08 0F 1B 02 1A 1A 0B 0A 1C 01 03 05 07 09 10 1B 03 1A 1A
				/*Power Sequence Option Configuration*/
				39 01 00 00 00 00 06 C9 05 5D 03 04 00
				/*GIP Setting*/
				39 01 00 00 00 00 1B E5 0B 0A 0C 00 02 04 06 08 0F 1B 02 1A 1A 0B 0A 0C 01 03 05 07 09 10 1B 03 1A 1A
				/*Black Frame Setting*/
				39 01 00 00 00 00 03 BD 01 05
				05 01 00 00 05 00 01 29
			];
		};
	};
};
